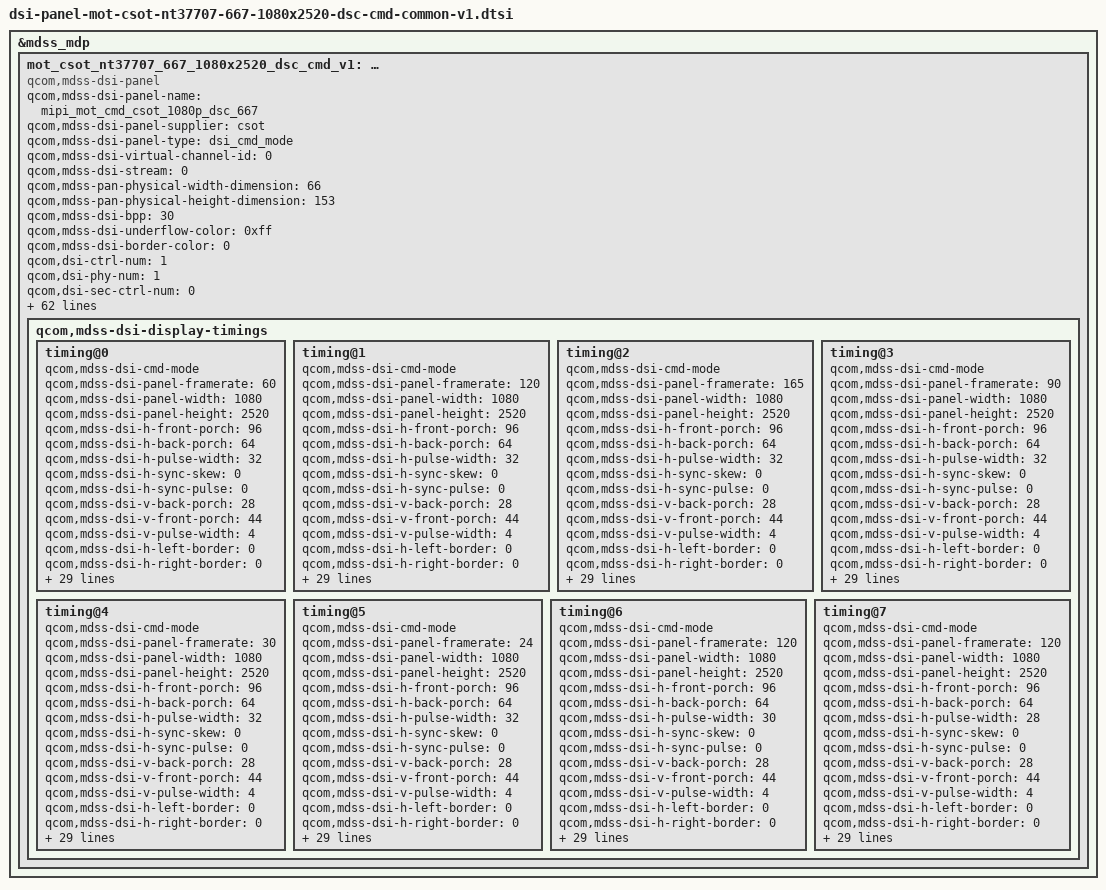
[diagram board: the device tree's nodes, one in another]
/* Copyright (c) 2019-2020, The Linux Foundation. All rights reserved.
 *
 * This program is free software; you can redistribute it and/or modify
 * it under the terms of the GNU General Public License version 2 and
 * only version 2 as published by the Free Software Foundation.
 *
 * This program is distributed in the hope that it will be useful,
 * but WITHOUT ANY WARRANTY; without even the implied warranty of
 * MERCHANTABILITY or FITNESS FOR A PARTICULAR PURPOSE.  See the
 * GNU General Public License for more details.
 */
&mdss_mdp {
mot_csot_nt37707_667_1080x2520_dsc_cmd_v1: qcom,mdss_dsi_mot_csot_nt37707_667_1080x2520_dsc_cmd_v1 {
compatible = "qcom,mdss-dsi-panel";
qcom,mdss-dsi-panel-name = "mipi_mot_cmd_csot_1080p_dsc_667";
qcom,mdss-dsi-panel-supplier = "csot";
qcom,mdss-dsi-panel-type = "dsi_cmd_mode";
qcom,mdss-dsi-virtual-channel-id = <0>;
qcom,mdss-dsi-stream = <0>;
qcom,mdss-pan-physical-width-dimension = <66>;
qcom,mdss-pan-physical-height-dimension = <153>;
qcom,mdss-dsi-bpp = <30>;
qcom,mdss-dsi-underflow-color = <0xff>;
qcom,mdss-dsi-border-color = <0>;

qcom,dsi-ctrl-num = <1>;
qcom,dsi-phy-num = <1>;
qcom,dsi-sec-ctrl-num = <0>;
qcom,dsi-sec-phy-num = <0>;

qcom,mdss-dsi-traffic-mode = "burst_mode";
qcom,mdss-dsi-bllp-eof-power-mode;
qcom,mdss-dsi-bllp-power-mode;
qcom,mdss-dsi-lane-0-state;
qcom,mdss-dsi-lane-1-state;
qcom,mdss-dsi-lane-2-state;
qcom,mdss-dsi-lane-3-state;

qcom,mdss-dsi-dma-trigger = "trigger_sw";
qcom,mdss-dsi-mdp-trigger = "none";
qcom,mdss-dsi-reset-sequence = <0 3>, <1 1>, <0 1>, <1 20>;
qcom,mdss-dsi-lp11-init;
qcom,mdss-dsi-tx-eot-append;
qcom,mdss-dsi-te-pin-select = <1>;
qcom,mdss-dsi-te-dcs-command = <1>;
qcom,mdss-dsi-te-using-te-pin;

//qcom,bklt-dcs-2bytes-enabled;
qcom,mdss-dsi-bl-min-level = <4>;
qcom,mdss-dsi-bl-max-level = <14056>;
qcom,mdss-dsi-bl-pmic-control-type = "bl_ctrl_dcs";

qcom,mdss-dsi-panel-hdr-enabled;
qcom,mdss-dsi-panel-hdr-color-primaries = <14500 15500 32000
	        17000 15500 30000 8000 3000>;
qcom,mdss-dsi-panel-peak-brightness = <4200000>;

qcom,mdss-dsi-panel-blackness-level = <3230>;

qcom,mdss-dsi-dc-off-command = [
		39 00 00 40 00 00 02 6F 01
		39 00 00 40 00 00 02 8B 00
		39 00 00 40 00 00 06 F0 55 AA 52 08 01
		39 00 00 40 00 00 02 6F 36
		39 00 00 40 00 00 07 C6 02 10 EE 1E 00 5E
		39 00 00 40 00 00 02 6F 6F
		39 00 00 00 00 00 07 E2 02 10 EE 1E 00 5E
		];

qcom,mdss-dsi-dc-off-command-state = "dsi_hs_mode";
qcom,mdss-dsi-dc-on-command = [
		39 00 00 40 00 00 02 6F 01
		39 00 00 40 00 00 02 8B 81
		39 00 00 40 00 00 06 F0 55 AA 52 08 01
		39 00 00 40 00 00 02 6F 36
		39 00 00 40 00 00 07 C6 02 10 EE 19 00 5E
		39 00 00 40 00 00 02 6F 6F
		39 00 00 00 00 00 07 E2 02 10 EE 19 00 5E
		];
qcom,mdss-dsi-dc-on-command-state = "dsi_hs_mode";
//qcom,mdss-dsi-nt37705-dc-detect-fps;
qcom,check_pcd;
qcom,pcd-reg-read-enabled;
qcom,pcd-reg-check-before-read;
qcom,mdss-dsi-panel-pcd-reg-read-length = <1>;
qcom,mdss-dsi-panel-pcd-reg-mask = <0xFF>;
qcom,mdss-dsi-panel-pcd-reg-command = [06 01 00 01 00 00 01 D0];
qcom,mdss-dsi-panel-pcd-reg-pass-array-size = <4>;
qcom,mdss-dsi-panel-pcd-reg-pass-array = <0x80 0x81 0x82 0x83>;
qcom,mdss-dsi-panel-pcd-reg-read-delay-ms = <60>;
qcom,mdss-dsi-panel-pcd-reg-seq-interval = <30>; //pcd reg read seq interval per screen on.
qcom,mdss-dsi-panel-pcd-check-time-interval-in-minutes = <480>; //480 minutes/8hours for pcd reg read time interval

qcom,apl-enabled;
qcom,mdss-dsi-panel-APL-THRESHOLD-BL = <15412>;
qcom,mdss-dsi-panel-APL-FUNC-ID = <0>;
qcom,mdss-dsi-panel-apl-on-command = [
		39 00 00 40 00 00 02 6F 07
		39 00 00 00 00 00 02 51 80
		];
qcom,mdss-dsi-panel-apl-off-command = [
		39 00 00 40 00 00 02 6F 07
		39 00 00 00 00 00 02 51 00
		];

qcom,mdss-dsi-hbm-off-command = [
		39 00 00 40 00 00 02 6F 07
		39 00 00 40 00 00 02 51 00
		39 00 00 00 00 00 03 51 2C 50
		];
qcom,mdss-dsi-hbm-off-command-state = "dsi_hs_mode";
qcom,mdss-dsi-hbm-on-command = [
		39 00 00 40 00 00 02 6F 07
		39 00 00 40 00 00 02 51 80
		39 00 00 00 00 00 03 51 3F FC
		];
qcom,mdss-dsi-hbm-on-command-state = "dsi_hs_mode";

qcom,mdss-dsi-display-timings {
	timing@0{
		qcom,mdss-dsi-cmd-mode;
		qcom,mdss-dsi-panel-framerate = <60>;
		qcom,mdss-dsi-panel-width = <1080>;
		qcom,mdss-dsi-panel-height = <2520>;
		qcom,mdss-dsi-h-front-porch = <96>;
		qcom,mdss-dsi-h-back-porch = <64>;
		qcom,mdss-dsi-h-pulse-width = <32>;
		qcom,mdss-dsi-h-sync-skew = <0>;
		qcom,mdss-dsi-h-sync-pulse = <0>;
		qcom,mdss-dsi-v-back-porch = <28>;
		qcom,mdss-dsi-v-front-porch = <44>;
		qcom,mdss-dsi-v-pulse-width = <4>;
		qcom,mdss-dsi-h-left-border = <0>;
		qcom,mdss-dsi-h-right-border = <0>;
		qcom,mdss-dsi-v-top-border = <0>;
		qcom,mdss-dsi-v-bottom-border = <0>;
		qcom,mdss-dsi-timing-switch-command = [
			39 00 00 40 00 00 02 6F 04
			39 00 00 40 00 00 02 35 00
			39 00 00 40 00 00 02 53 20
			39 00 00 40 00 00 02 5A 02
			39 00 00 40 00 00 02 2F 30
			39 00 00 40 00 00 03 6D 01 00
			39 00 00 40 00 00 02 6F 06
			39 00 00 40 00 00 02 6D 03
			39 00 00 40 00 00 02 6F 02
			39 00 00 40 00 00 02 8C 10
			39 00 00 00 11 00 02 8C 02
		];
		qcom,mdss-dsi-on-command = [
		39 00 00 40 00 00 06 F0 55 AA 52 08 01
		39 00 00 40 00 00 02 6F 2F
		39 00 00 40 00 00 02 C3 00
		39 00 00 40 00 00 02 6F 00
		39 00 00 40 00 00 06 C3 99 29 02 60 E3
		39 00 00 40 00 00 02 6F 06
		39 00 00 40 00 00 02 C3 29
		39 00 00 40 00 00 02 6F 08
		39 00 00 40 00 00 03 C3 60 E3
		39 00 00 40 00 00 02 6F 0B
		39 00 00 40 00 00 25 C3 3F 41 2A 3F 52 EB 3F 1D DF 3F 3B B0 3F 41 95 3F 0D 75 3F 4B 9A 3F 4C 43 3F 41 95 3F 0D 75 01 10 00 00 10 00
		39 00 00 40 00 00 02 6F 30
		39 00 00 40 00 00 06 C3 00 AA 02 AA 02
		39 00 00 40 00 00 02 6F 00
		39 00 00 40 00 00 02 C3 DD
		39 00 00 40 00 00 02 6F 04
		39 00 00 40 00 00 02 C3 07
		39 00 00 40 00 00 02 6F 09
		39 00 00 40 00 00 02 C3 07
		39 00 00 40 00 00 06 F0 55 AA 52 08 01
		39 00 00 40 00 00 04 C4 00 92 00
		39 00 00 40 00 00 02 6F 01
		39 00 00 40 00 00 02 8D 20
		39 00 00 40 00 00 02 6F 06
		39 00 00 40 00 00 02 8D 05
		39 00 00 40 00 00 06 F0 55 AA 52 08 00
		39 00 00 40 00 00 03 B2 09 60
		39 00 00 40 00 00 02 6F 05
		39 00 00 40 00 00 03 B2 05 05

		39 00 00 40 00 00 06 F0 55 AA 52 08 09
		39 00 00 40 00 00 03 D0 FF 00
		39 00 00 40 00 00 02 6F 02
		39 00 00 40 00 00 03 D0 06 64
		39 00 00 40 00 00 02 6F 04
		39 00 00 40 00 00 03 D0 09 04
		39 00 00 40 00 00 02 6F 06
		39 00 00 40 00 00 03 D0 0D BF
		39 00 00 40 00 00 02 6F 08
		39 00 00 40 00 00 03 D0 0D C0
		39 00 00 40 00 00 02 6F 0A
		39 00 00 40 00 00 03 D0 1D 24
		39 00 00 40 00 00 02 6F 0C
		39 00 00 40 00 00 03 D0 2C 50
		39 00 00 40 00 00 02 6F 0E
		39 00 00 40 00 00 07 D0 10 00 00 00 00 00
		39 00 00 40 00 00 02 6F 14
		39 00 00 40 00 00 07 D0 10 00 00 00 00 00
		39 00 00 40 00 00 02 6F 1A
		39 00 00 40 00 00 07 D0 00 00 00 00 00 00
		39 00 00 40 00 00 02 6F 20
		39 00 00 40 00 00 07 D0 00 00 00 00 00 00
		39 00 00 40 00 00 02 6F 26
		39 00 00 40 00 00 07 D0 1F 00 00 00 00 00
		39 00 00 40 00 00 02 6F 2C
		39 00 00 40 00 00 07 D0 1F 00 00 00 00 00
		39 00 00 40 00 00 02 6F 32
		39 00 00 40 00 00 07 D0 00 00 00 00 00 00
		39 00 00 40 00 00 02 6F 38
		39 00 00 40 00 00 07 D0 00 00 00 00 00 00
		39 00 00 40 00 00 02 62 80

		39 00 00 40 00 00 06 F0 55 AA 52 08 00
		39 00 00 40 00 00 02 6F 78
		39 00 00 40 00 00 18 B0 10 00 2A 00 C2 01 DA 03 7C 05 B1 08 80 0B EE 0F FF 05 55 05 56 05 55
		39 00 00 40 00 00 02 6F 6F
		39 00 00 40 00 00 07 B0 02 1C 04 38 02 1C
		39 00 00 40 00 00 06 F0 55 AA 52 08 08
		39 00 00 40 00 00 17 C1 8D FF DD FF FF DD FF FF DD FF FF DD FF FF DD FF FF AB FC 45 0D FF
		39 00 00 40 00 00 02 6F 23
		39 00 00 40 00 00 15 C1 0D FF DD FF FF DD FF FF DD FF FF DD FF FF DD FF FF AB FC 45
		39 00 00 40 00 00 02 6F 37
		39 00 00 40 00 00 15 C1 0D FF DD FF FF DD FF FF DD FF FF DD FF FF DD FF FF FF FF FF
		39 00 00 40 00 00 02 6F 4B
		39 00 00 40 00 00 15 C1 0D FF DD FF FF DD FF FF DD FF FF DD FF FF DD FF FF AB FC 45
		39 00 00 40 00 00 02 6F 5F
		39 00 00 40 00 00 15 C1 0D FF DD FF FF DD FF FF DD FF FF DD FF FF DD FF FF FF FF FF
		39 00 00 40 00 00 02 6F 73
		39 00 00 40 00 00 15 C1 0D FF DD FF FF DD FF FF DD FF FF DD FF FF DD FF FF AB FC 45
		39 00 00 40 00 00 11 BA 00 01 03 A4 03 A4 05 B8 05 B8 07 D8 07 D8 0A 84
		39 00 00 40 00 00 02 6F 10
		39 00 00 40 00 00 11 BA 0A 84 0D BF 0D BF 0D C0 0D C0 1D 24 1D 24 2C 50
		39 00 00 40 00 00 02 6F 20
		39 00 00 40 00 00 0D BA 2C 50 36 E8 36 E8 3C 34 3C 34 3F FC
		39 00 00 40 00 00 02 6F 20
		39 00 00 40 00 00 04 C1 04 52 CD
		39 00 00 40 00 00 02 6F 1D
		39 00 00 40 00 00 04 C1 00 80 FF
		39 00 00 40 00 00 02 6F 07
		39 00 00 40 00 00 02 51 00
		39 00 00 40 00 00 06 F0 55 AA 52 08 00
		39 00 00 40 00 00 02 C7 22
		39 00 00 40 00 00 02 6F 31
		39 00 00 40 00 00 03 C0 00 12
		39 00 00 40 00 00 02 6F 35
		39 00 00 40 00 00 03 C0 33 34
		39 00 00 40 00 00 06 F0 55 AA 52 08 04
		39 00 00 40 00 00 02 C0 20
		39 00 00 40 00 00 02 B1 01
		39 00 00 40 00 00 02 6F 0A
		39 00 00 40 00 00 02 B1 20
		39 00 00 40 00 00 02 6F 07
		39 00 00 40 00 00 04 B1 00 02 1C
		39 00 00 40 00 00 02 6F 0B
		39 00 00 40 00 00 02 B1 02
		39 00 00 40 00 00 02 C4 10
		39 00 00 40 00 00 05 FF AA 55 A5 80
		39 00 00 40 00 00 02 6F 0A
		39 00 00 40 00 00 06 F6 70 70 70 70 70
		39 00 00 40 00 00 02 6F 07
		39 00 00 40 00 00 02 F8 4D
		39 00 00 40 00 00 02 6F 23
		39 00 00 40 00 00 02 F8 4D
		39 00 00 40 00 00 05 FF AA 55 A5 81
		39 00 00 40 00 00 02 6F 0C
		39 00 00 40 00 00 02 FD 08
		39 00 00 40 00 00 02 6F 10
		39 00 00 40 00 00 02 FB 40
		39 00 00 40 00 00 02 6F 13
		39 00 00 40 00 00 02 F9 00
		39 00 00 40 00 00 02 17 30
		39 00 00 40 00 00 05 2A 00 00 04 37
		39 00 00 40 00 00 05 2B 00 00 09 D7
		39 00 00 40 00 00 02 90 03
		39 00 00 40 00 00 02 6F 01
		39 00 00 40 00 00 02 90 43
		39 00 00 40 00 00 13 91 AB A8 00 14 C2 00 02 0E 01 E8 00 07 05 0E 05 16 10 F0
		39 00 00 40 00 00 02 6F 06
		39 00 00 40 00 00 02 6D 04

		39 00 00 40 00 00 02 6F 04
		39 00 00 40 00 00 02 35 00
		39 00 00 40 00 00 02 53 20
		39 00 00 40 00 00 02 5A 02
		39 00 00 40 00 00 02 2F 30
		39 00 00 40 00 00 03 6D 01 00
		39 00 00 40 00 00 02 6F 06
		39 00 00 40 00 00 02 6D 03
		39 00 00 40 00 00 02 6F 02
		39 00 00 40 00 00 02 8C 10
		39 00 00 40 00 00 02 8C 02

		39 00 00 40 00 00 03 5F 00 00
		//39 00 00 40 00 00 02 35 00
		39 00 00 40 00 00 03 51 00 00
		39 00 00 40 00 00 02 6F 04
		39 00 00 40 00 00 03 51 3F FC
		//39 00 00 40 00 00 02 53 20
		39 00 00 40 00 00 06 F0 55 AA 52 08 01
		39 00 00 40 00 00 02 6F 02
		39 00 00 40 00 00 03 C7 00 00
		39 00 00 00 00 00 02 26 00
                05 00 00 00 78 00 01 11
                05 00 00 00 00 00 01 29];	/* display on */
		qcom,mdss-dsi-off-command = [
			05 00 00 00 00 00 01 28		/* display_off */
			05 00 00 00 64 00 01 10];	/* enter sleep mode */

		qcom,mdss-dsi-on-command-state = "dsi_lp_mode";
		qcom,mdss-dsi-off-command-state = "dsi_lp_mode";
		qcom,mdss-dsi-timing-switch-command-state =
			"dsi_hs_mode";
		qcom,compression-mode = "dsc";
		/* Why QCOM doesn't use this, even it used 2 encoder
		 * as for that dsi_sw43404_amoled_cmd, for ex */
		/* qcom,mdss-dsc-encoders = <2>; */
		qcom,mdss-dsc-version = <0x11>;
		qcom,mdss-dsc-slice-height = <20>;
		qcom,mdss-dsc-slice-width = <540>;
		qcom,mdss-dsc-slice-per-pkt = <2>;
		qcom,mdss-dsc-bit-per-component = <10>;
		qcom,mdss-dsc-bit-per-pixel = <8>;
		qcom,mdss-dsc-block-prediction-enable;
		qcom,mdss-dsc-novateck-ic;

		qcom,mdss-dsi-pcd-check-enable-command = [
			39 00 00 40 00 00 06 F0 55 AA 52 08 01
			39 00 00 40 00 00 02 6F 01
			39 00 00 00 00 00 06 D0 80 00 30 00 01
			];
		qcom,mdss-dsi-pcd-check-enable-command-state = "dsi_hs_mode";
		qcom,mdss-dsi-pcd-check-disable-command = [
			39 00 00 40 00 00 06 F0 55 AA 52 08 01
			39 00 00 40 00 00 02 6F 01
			39 00 00 00 00 00 06 D0 00 00 30 00 01
			];
		qcom,mdss-dsi-pcd-check-disable-command-state = "dsi_hs_mode";
	};

	timing@1{
		qcom,mdss-dsi-cmd-mode;
		qcom,mdss-dsi-panel-framerate = <120>;
		qcom,mdss-dsi-panel-width = <1080>;
		qcom,mdss-dsi-panel-height = <2520>;
		qcom,mdss-dsi-h-front-porch = <96>;
		qcom,mdss-dsi-h-back-porch = <64>;
		qcom,mdss-dsi-h-pulse-width = <32>;
		qcom,mdss-dsi-h-sync-skew = <0>;
		qcom,mdss-dsi-h-sync-pulse = <0>;
		qcom,mdss-dsi-v-back-porch = <28>;
		qcom,mdss-dsi-v-front-porch = <44>;
		qcom,mdss-dsi-v-pulse-width = <4>;
		qcom,mdss-dsi-h-left-border = <0>;
		qcom,mdss-dsi-h-right-border = <0>;
		qcom,mdss-dsi-v-top-border = <0>;
		qcom,mdss-dsi-v-bottom-border = <0>;
		qcom,mdss-dsi-timing-switch-command = [
			39 00 00 40 00 00 02 6F 04
			39 00 00 40 00 00 02 35 00
			39 00 00 40 00 00 02 53 20
			39 00 00 00 09 00 02 2F 00
		];
		qcom,mdss-dsi-on-command = [
		39 00 00 40 00 00 06 F0 55 AA 52 08 01
		39 00 00 40 00 00 02 6F 2F
		39 00 00 40 00 00 02 C3 00
		39 00 00 40 00 00 02 6F 00
		39 00 00 40 00 00 06 C3 99 29 02 60 E3
		39 00 00 40 00 00 02 6F 06
		39 00 00 40 00 00 02 C3 29
		39 00 00 40 00 00 02 6F 08
		39 00 00 40 00 00 03 C3 60 E3
		39 00 00 40 00 00 02 6F 0B
		39 00 00 40 00 00 25 C3 3F 41 2A 3F 52 EB 3F 1D DF 3F 3B B0 3F 41 95 3F 0D 75 3F 4B 9A 3F 4C 43 3F 41 95 3F 0D 75 01 10 00 00 10 00
		39 00 00 40 00 00 02 6F 30
		39 00 00 40 00 00 06 C3 00 AA 02 AA 02
		39 00 00 40 00 00 02 6F 00
		39 00 00 40 00 00 02 C3 DD
		39 00 00 40 00 00 02 6F 04
		39 00 00 40 00 00 02 C3 07
		39 00 00 40 00 00 02 6F 09
		39 00 00 40 00 00 02 C3 07
		39 00 00 40 00 00 06 F0 55 AA 52 08 01
		39 00 00 40 00 00 04 C4 00 92 00
		39 00 00 40 00 00 02 6F 06
		39 00 00 40 00 00 02 8D 05
		39 00 00 40 00 00 06 F0 55 AA 52 08 00
		39 00 00 40 00 00 03 B2 09 60
		39 00 00 40 00 00 02 6F 05
		39 00 00 40 00 00 03 B2 05 05

		39 00 00 40 00 00 06 F0 55 AA 52 08 09
		39 00 00 40 00 00 03 D0 FF 00
		39 00 00 40 00 00 02 6F 02
		39 00 00 40 00 00 03 D0 06 64
		39 00 00 40 00 00 02 6F 04
		39 00 00 40 00 00 03 D0 09 04
		39 00 00 40 00 00 02 6F 06
		39 00 00 40 00 00 03 D0 0D BF
		39 00 00 40 00 00 02 6F 08
		39 00 00 40 00 00 03 D0 0D C0
		39 00 00 40 00 00 02 6F 0A
		39 00 00 40 00 00 03 D0 1D 24
		39 00 00 40 00 00 02 6F 0C
		39 00 00 40 00 00 03 D0 2C 50
		39 00 00 40 00 00 02 6F 0E
		39 00 00 40 00 00 07 D0 10 00 00 00 00 00
		39 00 00 40 00 00 02 6F 14
		39 00 00 40 00 00 07 D0 10 00 00 00 00 00
		39 00 00 40 00 00 02 6F 1A
		39 00 00 40 00 00 07 D0 00 00 00 00 00 00
		39 00 00 40 00 00 02 6F 20
		39 00 00 40 00 00 07 D0 00 00 00 00 00 00
		39 00 00 40 00 00 02 6F 26
		39 00 00 40 00 00 07 D0 1F 00 00 00 00 00
		39 00 00 40 00 00 02 6F 2C
		39 00 00 40 00 00 07 D0 1F 00 00 00 00 00
		39 00 00 40 00 00 02 6F 32
		39 00 00 40 00 00 07 D0 00 00 00 00 00 00
		39 00 00 40 00 00 02 6F 38
		39 00 00 40 00 00 07 D0 00 00 00 00 00 00
		39 00 00 40 00 00 02 62 80

		39 00 00 40 00 00 06 F0 55 AA 52 08 00
		39 00 00 40 00 00 02 6F 78
		39 00 00 40 00 00 18 B0 10 00 2A 00 C2 01 DA 03 7C 05 B1 08 80 0B EE 0F FF 05 55 05 56 05 55
		39 00 00 40 00 00 02 6F 6F
		39 00 00 40 00 00 07 B0 02 1C 04 38 02 1C
		39 00 00 40 00 00 06 F0 55 AA 52 08 08
		39 00 00 40 00 00 17 C1 8D FF DD FF FF DD FF FF DD FF FF DD FF FF DD FF FF AB FC 45 0D FF
		39 00 00 40 00 00 02 6F 23
		39 00 00 40 00 00 15 C1 0D FF DD FF FF DD FF FF DD FF FF DD FF FF DD FF FF AB FC 45
		39 00 00 40 00 00 02 6F 37
		39 00 00 40 00 00 15 C1 0D FF DD FF FF DD FF FF DD FF FF DD FF FF DD FF FF FF FF FF
		39 00 00 40 00 00 02 6F 4B
		39 00 00 40 00 00 15 C1 0D FF DD FF FF DD FF FF DD FF FF DD FF FF DD FF FF AB FC 45
		39 00 00 40 00 00 02 6F 5F
		39 00 00 40 00 00 15 C1 0D FF DD FF FF DD FF FF DD FF FF DD FF FF DD FF FF FF FF FF
		39 00 00 40 00 00 02 6F 73
		39 00 00 40 00 00 15 C1 0D FF DD FF FF DD FF FF DD FF FF DD FF FF DD FF FF AB FC 45
		39 00 00 40 00 00 11 BA 00 01 03 A4 03 A4 05 B8 05 B8 07 D8 07 D8 0A 84
		39 00 00 40 00 00 02 6F 10
		39 00 00 40 00 00 11 BA 0A 84 0D BF 0D BF 0D C0 0D C0 1D 24 1D 24 2C 50
		39 00 00 40 00 00 02 6F 20
		39 00 00 40 00 00 0D BA 2C 50 36 E8 36 E8 3C 34 3C 34 3F FC
		39 00 00 40 00 00 02 6F 20
		39 00 00 40 00 00 04 C1 04 52 CD
		39 00 00 40 00 00 02 6F 1D
		39 00 00 40 00 00 04 C1 00 80 FF
		39 00 00 40 00 00 02 6F 07
		39 00 00 40 00 00 02 51 00
		39 00 00 40 00 00 06 F0 55 AA 52 08 00
		39 00 00 40 00 00 02 C7 22
		39 00 00 40 00 00 02 6F 31
		39 00 00 40 00 00 03 C0 00 12
		39 00 00 40 00 00 02 6F 35
		39 00 00 40 00 00 03 C0 33 34
		39 00 00 40 00 00 06 F0 55 AA 52 08 04
		39 00 00 40 00 00 02 C0 20
		39 00 00 40 00 00 02 B1 01
		39 00 00 40 00 00 02 6F 0A
		39 00 00 40 00 00 02 B1 20
		39 00 00 40 00 00 02 6F 07
		39 00 00 40 00 00 04 B1 00 02 1C
		39 00 00 40 00 00 02 6F 0B
		39 00 00 40 00 00 02 B1 02
		39 00 00 40 00 00 02 C4 10
		39 00 00 40 00 00 05 FF AA 55 A5 80
		39 00 00 40 00 00 02 6F 0A
		39 00 00 40 00 00 06 F6 70 70 70 70 70
		39 00 00 40 00 00 02 6F 07
		39 00 00 40 00 00 02 F8 4D
		39 00 00 40 00 00 02 6F 23
		39 00 00 40 00 00 02 F8 4D
		39 00 00 40 00 00 05 FF AA 55 A5 81
		39 00 00 40 00 00 02 6F 0C
		39 00 00 40 00 00 02 FD 08
		39 00 00 40 00 00 02 6F 10
		39 00 00 40 00 00 02 FB 40
		39 00 00 40 00 00 02 6F 13
		39 00 00 40 00 00 02 F9 00
		39 00 00 40 00 00 02 17 30
		39 00 00 40 00 00 05 2A 00 00 04 37
		39 00 00 40 00 00 05 2B 00 00 09 D7
		39 00 00 40 00 00 02 90 03
		39 00 00 40 00 00 02 6F 01
		39 00 00 40 00 00 02 90 43
		39 00 00 40 00 00 13 91 AB A8 00 14 C2 00 02 0E 01 E8 00 07 05 0E 05 16 10 F0
		39 00 00 40 00 00 02 6F 06
		39 00 00 40 00 00 02 6D 04

		39 00 00 40 00 00 02 6F 04
		39 00 00 40 00 00 02 35 00
		39 00 00 40 00 00 02 53 20
		39 00 00 40 00 00 02 2F 00

		39 00 00 40 00 00 03 5F 00 00
		//39 00 00 40 00 00 02 35 00
		39 00 00 40 00 00 03 51 00 00
		39 00 00 40 00 00 02 6F 04
		39 00 00 40 00 00 03 51 3F FC
		//39 00 00 40 00 00 02 53 20
		39 00 00 40 00 00 06 F0 55 AA 52 08 01
		39 00 00 40 00 00 02 6F 02
		39 00 00 40 00 00 03 C7 00 00
		39 00 00 00 00 00 02 26 00
                05 00 00 00 78 00 01 11
                05 00 00 00 00 00 01 29];	/* display on */
		qcom,mdss-dsi-off-command = [
			05 00 00 00 00 00 01 28		/* display_off */
			05 00 00 00 78 00 01 10];	/* enter sleep mode */

		qcom,mdss-dsi-on-command-state = "dsi_lp_mode";
		qcom,mdss-dsi-off-command-state = "dsi_lp_mode";
		qcom,mdss-dsi-timing-switch-command-state =
			"dsi_hs_mode";
		qcom,compression-mode = "dsc";
		/* Why QCOM doesn't use this, even it used 2 encoder
		 * as for that dsi_sw43404_amoled_cmd, for ex */
		/* qcom,mdss-dsc-encoders = <2>; */
		qcom,mdss-dsc-version = <0x11>;
		qcom,mdss-dsc-slice-height = <20>;
		qcom,mdss-dsc-slice-width = <540>;
		qcom,mdss-dsc-slice-per-pkt = <2>;
		qcom,mdss-dsc-bit-per-component = <10>;
		qcom,mdss-dsc-bit-per-pixel = <8>;
		qcom,mdss-dsc-block-prediction-enable;
		qcom,mdss-dsc-novateck-ic;

		qcom,mdss-dsi-pcd-check-enable-command = [
			39 00 00 40 00 00 06 F0 55 AA 52 08 01
			39 00 00 40 00 00 02 6F 01
			39 00 00 00 00 00 06 D0 80 00 30 00 01
			];
		qcom,mdss-dsi-pcd-check-enable-command-state = "dsi_hs_mode";
		qcom,mdss-dsi-pcd-check-disable-command = [
			39 00 00 40 00 00 06 F0 55 AA 52 08 01
			39 00 00 40 00 00 02 6F 01
			39 00 00 00 00 00 06 D0 00 00 30 00 01
			];
		qcom,mdss-dsi-pcd-check-disable-command-state = "dsi_hs_mode";
	};

	timing@2{
		qcom,mdss-dsi-cmd-mode;
		qcom,mdss-dsi-panel-framerate = <165>;
		qcom,mdss-dsi-panel-width = <1080>;
		qcom,mdss-dsi-panel-height = <2520>;
		qcom,mdss-dsi-h-front-porch = <96>;
		qcom,mdss-dsi-h-back-porch = <64>;
		qcom,mdss-dsi-h-pulse-width = <32>;
		qcom,mdss-dsi-h-sync-skew = <0>;
		qcom,mdss-dsi-h-sync-pulse = <0>;
		qcom,mdss-dsi-v-back-porch = <28>;
		qcom,mdss-dsi-v-front-porch = <44>;
		qcom,mdss-dsi-v-pulse-width = <4>;
		qcom,mdss-dsi-h-left-border = <0>;
		qcom,mdss-dsi-h-right-border = <0>;
		qcom,mdss-dsi-v-top-border = <0>;
		qcom,mdss-dsi-v-bottom-border = <0>;
		qcom,mdss-dsi-timing-switch-command = [
			39 00 00 40 00 00 02 6F 04
			39 00 00 40 00 00 02 35 00
			39 00 00 40 00 00 02 53 20
			39 00 00 00 00 00 02 2F 03
		];
		qcom,mdss-dsi-on-command = [
		39 00 00 40 00 00 06 F0 55 AA 52 08 01
		39 00 00 40 00 00 02 6F 2F
		39 00 00 40 00 00 02 C3 00
		39 00 00 40 00 00 02 6F 00
		39 00 00 40 00 00 06 C3 99 29 02 60 E3
		39 00 00 40 00 00 02 6F 06
		39 00 00 40 00 00 02 C3 29
		39 00 00 40 00 00 02 6F 08
		39 00 00 40 00 00 03 C3 60 E3
		39 00 00 40 00 00 02 6F 0B
		39 00 00 40 00 00 25 C3 3F 41 2A 3F 52 EB 3F 1D DF 3F 3B B0 3F 41 95 3F 0D 75 3F 4B 9A 3F 4C 43 3F 41 95 3F 0D 75 01 10 00 00 10 00
		39 00 00 40 00 00 02 6F 30
		39 00 00 40 00 00 06 C3 00 AA 02 AA 02
		39 00 00 40 00 00 02 6F 00
		39 00 00 40 00 00 02 C3 DD
		39 00 00 40 00 00 02 6F 04
		39 00 00 40 00 00 02 C3 07
		39 00 00 40 00 00 02 6F 09
		39 00 00 40 00 00 02 C3 07
		39 00 00 40 00 00 06 F0 55 AA 52 08 01
		39 00 00 40 00 00 04 C4 00 92 00
		39 00 00 40 00 00 02 6F 06
		39 00 00 40 00 00 02 8D 05
		39 00 00 40 00 00 06 F0 55 AA 52 08 00
		39 00 00 40 00 00 03 B2 09 60
		39 00 00 40 00 00 02 6F 05
		39 00 00 40 00 00 03 B2 05 05

		39 00 00 40 00 00 06 F0 55 AA 52 08 09
		39 00 00 40 00 00 03 D0 FF 00
		39 00 00 40 00 00 02 6F 02
		39 00 00 40 00 00 03 D0 06 64
		39 00 00 40 00 00 02 6F 04
		39 00 00 40 00 00 03 D0 09 04
		39 00 00 40 00 00 02 6F 06
		39 00 00 40 00 00 03 D0 0D BF
		39 00 00 40 00 00 02 6F 08
		39 00 00 40 00 00 03 D0 0D C0
		39 00 00 40 00 00 02 6F 0A
		39 00 00 40 00 00 03 D0 1D 24
		39 00 00 40 00 00 02 6F 0C
		39 00 00 40 00 00 03 D0 2C 50
		39 00 00 40 00 00 02 6F 0E
		39 00 00 40 00 00 07 D0 10 00 00 00 00 00
		39 00 00 40 00 00 02 6F 14
		39 00 00 40 00 00 07 D0 10 00 00 00 00 00
		39 00 00 40 00 00 02 6F 1A
		39 00 00 40 00 00 07 D0 00 00 00 00 00 00
		39 00 00 40 00 00 02 6F 20
		39 00 00 40 00 00 07 D0 00 00 00 00 00 00
		39 00 00 40 00 00 02 6F 26
		39 00 00 40 00 00 07 D0 1F 00 00 00 00 00
		39 00 00 40 00 00 02 6F 2C
		39 00 00 40 00 00 07 D0 1F 00 00 00 00 00
		39 00 00 40 00 00 02 6F 32
		39 00 00 40 00 00 07 D0 00 00 00 00 00 00
		39 00 00 40 00 00 02 6F 38
		39 00 00 40 00 00 07 D0 00 00 00 00 00 00
		39 00 00 40 00 00 02 62 80

		39 00 00 40 00 00 06 F0 55 AA 52 08 00
		39 00 00 40 00 00 02 6F 78
		39 00 00 40 00 00 18 B0 10 00 2A 00 C2 01 DA 03 7C 05 B1 08 80 0B EE 0F FF 05 55 05 56 05 55
		39 00 00 40 00 00 02 6F 6F
		39 00 00 40 00 00 07 B0 02 1C 04 38 02 1C
		39 00 00 40 00 00 06 F0 55 AA 52 08 08
		39 00 00 40 00 00 17 C1 8D FF DD FF FF DD FF FF DD FF FF DD FF FF DD FF FF AB FC 45 0D FF
		39 00 00 40 00 00 02 6F 23
		39 00 00 40 00 00 15 C1 0D FF DD FF FF DD FF FF DD FF FF DD FF FF DD FF FF AB FC 45
		39 00 00 40 00 00 02 6F 37
		39 00 00 40 00 00 15 C1 0D FF DD FF FF DD FF FF DD FF FF DD FF FF DD FF FF FF FF FF
		39 00 00 40 00 00 02 6F 4B
		39 00 00 40 00 00 15 C1 0D FF DD FF FF DD FF FF DD FF FF DD FF FF DD FF FF AB FC 45
		39 00 00 40 00 00 02 6F 5F
		39 00 00 40 00 00 15 C1 0D FF DD FF FF DD FF FF DD FF FF DD FF FF DD FF FF FF FF FF
		39 00 00 40 00 00 02 6F 73
		39 00 00 40 00 00 15 C1 0D FF DD FF FF DD FF FF DD FF FF DD FF FF DD FF FF AB FC 45
		39 00 00 40 00 00 11 BA 00 01 03 A4 03 A4 05 B8 05 B8 07 D8 07 D8 0A 84
		39 00 00 40 00 00 02 6F 10
		39 00 00 40 00 00 11 BA 0A 84 0D BF 0D BF 0D C0 0D C0 1D 24 1D 24 2C 50
		39 00 00 40 00 00 02 6F 20
		39 00 00 40 00 00 0D BA 2C 50 36 E8 36 E8 3C 34 3C 34 3F FC
		39 00 00 40 00 00 02 6F 20
		39 00 00 40 00 00 04 C1 04 52 CD
		39 00 00 40 00 00 02 6F 1D
		39 00 00 40 00 00 04 C1 00 80 FF
		39 00 00 40 00 00 02 6F 07
		39 00 00 40 00 00 02 51 00
		39 00 00 40 00 00 06 F0 55 AA 52 08 00
		39 00 00 40 00 00 02 C7 22
		39 00 00 40 00 00 02 6F 31
		39 00 00 40 00 00 03 C0 00 12
		39 00 00 40 00 00 02 6F 35
		39 00 00 40 00 00 03 C0 33 34
		39 00 00 40 00 00 06 F0 55 AA 52 08 04
		39 00 00 40 00 00 02 C0 20
		39 00 00 40 00 00 02 B1 01
		39 00 00 40 00 00 02 6F 0A
		39 00 00 40 00 00 02 B1 20
		39 00 00 40 00 00 02 6F 07
		39 00 00 40 00 00 04 B1 00 02 1C
		39 00 00 40 00 00 02 6F 0B
		39 00 00 40 00 00 02 B1 02
		39 00 00 40 00 00 02 C4 10
		39 00 00 40 00 00 05 FF AA 55 A5 80
		39 00 00 40 00 00 02 6F 0A
		39 00 00 40 00 00 06 F6 70 70 70 70 70
		39 00 00 40 00 00 02 6F 07
		39 00 00 40 00 00 02 F8 4D
		39 00 00 40 00 00 02 6F 23
		39 00 00 40 00 00 02 F8 4D
		39 00 00 40 00 00 05 FF AA 55 A5 81
		39 00 00 40 00 00 02 6F 0C
		39 00 00 40 00 00 02 FD 08
		39 00 00 40 00 00 02 6F 10
		39 00 00 40 00 00 02 FB 40
		39 00 00 40 00 00 02 6F 13
		39 00 00 40 00 00 02 F9 00
		39 00 00 40 00 00 02 17 30
		39 00 00 40 00 00 05 2A 00 00 04 37
		39 00 00 40 00 00 05 2B 00 00 09 D7
		39 00 00 40 00 00 02 90 03
		39 00 00 40 00 00 02 6F 01
		39 00 00 40 00 00 02 90 43
		39 00 00 40 00 00 13 91 AB A8 00 14 C2 00 02 0E 01 E8 00 07 05 0E 05 16 10 F0
		39 00 00 40 00 00 02 6F 06
		39 00 00 40 00 00 02 6D 04

		39 00 00 40 00 00 02 6F 04
		39 00 00 40 00 00 02 35 00
		39 00 00 40 00 00 02 53 20
		39 00 00 40 00 00 02 2F 03

		39 00 00 40 00 00 03 5F 00 00
		//39 00 00 40 00 00 02 35 00
		39 00 00 40 00 00 03 51 00 00
		39 00 00 40 00 00 02 6F 04
		39 00 00 40 00 00 03 51 3F FC
		//39 00 00 40 00 00 02 53 20
		39 00 00 40 00 00 06 F0 55 AA 52 08 01
		39 00 00 40 00 00 02 6F 02
		39 00 00 40 00 00 03 C7 00 00
		39 00 00 00 00 00 02 26 00
                05 00 00 00 78 00 01 11
                05 00 00 00 00 00 01 29];	/* display on */
		qcom,mdss-dsi-off-command = [
			05 00 00 00 00 00 01 28		/* display_off */
			05 00 00 00 64 00 01 10];	/* enter sleep mode */

		qcom,mdss-dsi-on-command-state = "dsi_lp_mode";
		qcom,mdss-dsi-off-command-state = "dsi_lp_mode";
		qcom,mdss-dsi-timing-switch-command-state =
			"dsi_hs_mode";
		qcom,compression-mode = "dsc";
		/* Why QCOM doesn't use this, even it used 2 encoder
		 * as for that dsi_sw43404_amoled_cmd, for ex */
		/* qcom,mdss-dsc-encoders = <2>; */
		qcom,mdss-dsc-version = <0x11>;
		qcom,mdss-dsc-slice-height = <20>;
		qcom,mdss-dsc-slice-width = <540>;
		qcom,mdss-dsc-slice-per-pkt = <2>;
		qcom,mdss-dsc-bit-per-component = <10>;
		qcom,mdss-dsc-bit-per-pixel = <8>;
		qcom,mdss-dsc-block-prediction-enable;
		qcom,mdss-dsc-novateck-ic;

		qcom,mdss-dsi-pcd-check-enable-command = [
			39 00 00 40 00 00 06 F0 55 AA 52 08 01
			39 00 00 40 00 00 02 6F 01
			39 00 00 00 00 00 06 D0 80 00 30 00 01
			];
		qcom,mdss-dsi-pcd-check-enable-command-state = "dsi_hs_mode";
		qcom,mdss-dsi-pcd-check-disable-command = [
			39 00 00 40 00 00 06 F0 55 AA 52 08 01
			39 00 00 40 00 00 02 6F 01
			39 00 00 00 00 00 06 D0 00 00 30 00 01
			];
		qcom,mdss-dsi-pcd-check-disable-command-state = "dsi_hs_mode";
	};

	timing@3{
		qcom,mdss-dsi-cmd-mode;
		qcom,mdss-dsi-panel-framerate = <90>;
		qcom,mdss-dsi-panel-width = <1080>;
		qcom,mdss-dsi-panel-height = <2520>;
		qcom,mdss-dsi-h-front-porch = <96>;
		qcom,mdss-dsi-h-back-porch = <64>;
		qcom,mdss-dsi-h-pulse-width = <32>;
		qcom,mdss-dsi-h-sync-skew = <0>;
		qcom,mdss-dsi-h-sync-pulse = <0>;
		qcom,mdss-dsi-v-back-porch = <28>;
		qcom,mdss-dsi-v-front-porch = <44>;
		qcom,mdss-dsi-v-pulse-width = <4>;
		qcom,mdss-dsi-h-left-border = <0>;
		qcom,mdss-dsi-h-right-border = <0>;
		qcom,mdss-dsi-v-top-border = <0>;
		qcom,mdss-dsi-v-bottom-border = <0>;
		qcom,mdss-dsi-timing-switch-command = [
			39 00 00 40 00 00 02 6F 04
			39 00 00 40 00 00 02 35 00
			39 00 00 40 00 00 02 53 20
			39 00 00 00 0C 00 02 2F 01
		];
		qcom,mdss-dsi-on-command = [
		39 00 00 40 00 00 06 F0 55 AA 52 08 01
		39 00 00 40 00 00 02 6F 2F
		39 00 00 40 00 00 02 C3 00
		39 00 00 40 00 00 02 6F 00
		39 00 00 40 00 00 06 C3 99 29 02 60 E3
		39 00 00 40 00 00 02 6F 06
		39 00 00 40 00 00 02 C3 29
		39 00 00 40 00 00 02 6F 08
		39 00 00 40 00 00 03 C3 60 E3
		39 00 00 40 00 00 02 6F 0B
		39 00 00 40 00 00 25 C3 3F 41 2A 3F 52 EB 3F 1D DF 3F 3B B0 3F 41 95 3F 0D 75 3F 4B 9A 3F 4C 43 3F 41 95 3F 0D 75 01 10 00 00 10 00
		39 00 00 40 00 00 02 6F 30
		39 00 00 40 00 00 06 C3 00 AA 02 AA 02
		39 00 00 40 00 00 02 6F 00
		39 00 00 40 00 00 02 C3 DD
		39 00 00 40 00 00 02 6F 04
		39 00 00 40 00 00 02 C3 07
		39 00 00 40 00 00 02 6F 09
		39 00 00 40 00 00 02 C3 07
		39 00 00 40 00 00 06 F0 55 AA 52 08 01
		39 00 00 40 00 00 04 C4 00 92 00
		39 00 00 40 00 00 02 6F 06
		39 00 00 40 00 00 02 8D 05
		39 00 00 40 00 00 06 F0 55 AA 52 08 00
		39 00 00 40 00 00 03 B2 09 60
		39 00 00 40 00 00 02 6F 05
		39 00 00 40 00 00 03 B2 05 05

		39 00 00 40 00 00 06 F0 55 AA 52 08 09
		39 00 00 40 00 00 03 D0 FF 00
		39 00 00 40 00 00 02 6F 02
		39 00 00 40 00 00 03 D0 06 64
		39 00 00 40 00 00 02 6F 04
		39 00 00 40 00 00 03 D0 09 04
		39 00 00 40 00 00 02 6F 06
		39 00 00 40 00 00 03 D0 0D BF
		39 00 00 40 00 00 02 6F 08
		39 00 00 40 00 00 03 D0 0D C0
		39 00 00 40 00 00 02 6F 0A
		39 00 00 40 00 00 03 D0 1D 24
		39 00 00 40 00 00 02 6F 0C
		39 00 00 40 00 00 03 D0 2C 50
		39 00 00 40 00 00 02 6F 0E
		39 00 00 40 00 00 07 D0 10 00 00 00 00 00
		39 00 00 40 00 00 02 6F 14
		39 00 00 40 00 00 07 D0 10 00 00 00 00 00
		39 00 00 40 00 00 02 6F 1A
		39 00 00 40 00 00 07 D0 00 00 00 00 00 00
		39 00 00 40 00 00 02 6F 20
		39 00 00 40 00 00 07 D0 00 00 00 00 00 00
		39 00 00 40 00 00 02 6F 26
		39 00 00 40 00 00 07 D0 1F 00 00 00 00 00
		39 00 00 40 00 00 02 6F 2C
		39 00 00 40 00 00 07 D0 1F 00 00 00 00 00
		39 00 00 40 00 00 02 6F 32
		39 00 00 40 00 00 07 D0 00 00 00 00 00 00
		39 00 00 40 00 00 02 6F 38
		39 00 00 40 00 00 07 D0 00 00 00 00 00 00
		39 00 00 40 00 00 02 62 80

		39 00 00 40 00 00 06 F0 55 AA 52 08 00
		39 00 00 40 00 00 02 6F 78
		39 00 00 40 00 00 18 B0 10 00 2A 00 C2 01 DA 03 7C 05 B1 08 80 0B EE 0F FF 05 55 05 56 05 55
		39 00 00 40 00 00 02 6F 6F
		39 00 00 40 00 00 07 B0 02 1C 04 38 02 1C
		39 00 00 40 00 00 06 F0 55 AA 52 08 08
		39 00 00 40 00 00 17 C1 8D FF DD FF FF DD FF FF DD FF FF DD FF FF DD FF FF AB FC 45 0D FF
		39 00 00 40 00 00 02 6F 23
		39 00 00 40 00 00 15 C1 0D FF DD FF FF DD FF FF DD FF FF DD FF FF DD FF FF AB FC 45
		39 00 00 40 00 00 02 6F 37
		39 00 00 40 00 00 15 C1 0D FF DD FF FF DD FF FF DD FF FF DD FF FF DD FF FF FF FF FF
		39 00 00 40 00 00 02 6F 4B
		39 00 00 40 00 00 15 C1 0D FF DD FF FF DD FF FF DD FF FF DD FF FF DD FF FF AB FC 45
		39 00 00 40 00 00 02 6F 5F
		39 00 00 40 00 00 15 C1 0D FF DD FF FF DD FF FF DD FF FF DD FF FF DD FF FF FF FF FF
		39 00 00 40 00 00 02 6F 73
		39 00 00 40 00 00 15 C1 0D FF DD FF FF DD FF FF DD FF FF DD FF FF DD FF FF AB FC 45
		39 00 00 40 00 00 11 BA 00 01 03 A4 03 A4 05 B8 05 B8 07 D8 07 D8 0A 84
		39 00 00 40 00 00 02 6F 10
		39 00 00 40 00 00 11 BA 0A 84 0D BF 0D BF 0D C0 0D C0 1D 24 1D 24 2C 50
		39 00 00 40 00 00 02 6F 20
		39 00 00 40 00 00 0D BA 2C 50 36 E8 36 E8 3C 34 3C 34 3F FC
		39 00 00 40 00 00 02 6F 20
		39 00 00 40 00 00 04 C1 04 52 CD
		39 00 00 40 00 00 02 6F 1D
		39 00 00 40 00 00 04 C1 00 80 FF
		39 00 00 40 00 00 02 6F 07
		39 00 00 40 00 00 02 51 00
		39 00 00 40 00 00 06 F0 55 AA 52 08 00
		39 00 00 40 00 00 02 C7 22
		39 00 00 40 00 00 02 6F 31
		39 00 00 40 00 00 03 C0 00 12
		39 00 00 40 00 00 02 6F 35
		39 00 00 40 00 00 03 C0 33 34
		39 00 00 40 00 00 06 F0 55 AA 52 08 04
		39 00 00 40 00 00 02 C0 20
		39 00 00 40 00 00 02 B1 01
		39 00 00 40 00 00 02 6F 0A
		39 00 00 40 00 00 02 B1 20
		39 00 00 40 00 00 02 6F 07
		39 00 00 40 00 00 04 B1 00 02 1C
		39 00 00 40 00 00 02 6F 0B
		39 00 00 40 00 00 02 B1 02
		39 00 00 40 00 00 02 C4 10
		39 00 00 40 00 00 05 FF AA 55 A5 80
		39 00 00 40 00 00 02 6F 0A
		39 00 00 40 00 00 06 F6 70 70 70 70 70
		39 00 00 40 00 00 02 6F 07
		39 00 00 40 00 00 02 F8 4D
		39 00 00 40 00 00 02 6F 23
		39 00 00 40 00 00 02 F8 4D
		39 00 00 40 00 00 05 FF AA 55 A5 81
		39 00 00 40 00 00 02 6F 0C
		39 00 00 40 00 00 02 FD 08
		39 00 00 40 00 00 02 6F 10
		39 00 00 40 00 00 02 FB 40
		39 00 00 40 00 00 02 6F 13
		39 00 00 40 00 00 02 F9 00
		39 00 00 40 00 00 02 17 30
		39 00 00 40 00 00 05 2A 00 00 04 37
		39 00 00 40 00 00 05 2B 00 00 09 D7
		39 00 00 40 00 00 02 90 03
		39 00 00 40 00 00 02 6F 01
		39 00 00 40 00 00 02 90 43
		39 00 00 40 00 00 13 91 AB A8 00 14 C2 00 02 0E 01 E8 00 07 05 0E 05 16 10 F0
		39 00 00 40 00 00 02 6F 06
		39 00 00 40 00 00 02 6D 04

		39 00 00 40 00 00 02 6F 04
		39 00 00 40 00 00 02 35 00
		39 00 00 40 00 00 02 53 20
		39 00 00 40 00 00 02 2F 01

		39 00 00 40 00 00 03 5F 00 00
		//39 00 00 40 00 00 02 35 00
		39 00 00 40 00 00 03 51 00 00
		39 00 00 40 00 00 02 6F 04
		39 00 00 40 00 00 03 51 3F FC
		//39 00 00 40 00 00 02 53 20
		39 00 00 40 00 00 06 F0 55 AA 52 08 01
		39 00 00 40 00 00 02 6F 02
		39 00 00 40 00 00 03 C7 00 00
		39 00 00 00 00 00 02 26 00
                05 00 00 00 78 00 01 11
                05 00 00 00 00 00 01 29];	/* display on */
		qcom,mdss-dsi-off-command = [
			05 00 00 00 00 00 01 28		/* display_off */
			05 00 00 00 64 00 01 10];	/* enter sleep mode */

		qcom,mdss-dsi-on-command-state = "dsi_lp_mode";
		qcom,mdss-dsi-off-command-state = "dsi_lp_mode";
		qcom,mdss-dsi-timing-switch-command-state =
			"dsi_hs_mode";
		qcom,compression-mode = "dsc";
		/* Why QCOM doesn't use this, even it used 2 encoder
		 * as for that dsi_sw43404_amoled_cmd, for ex */
		/* qcom,mdss-dsc-encoders = <2>; */
		qcom,mdss-dsc-version = <0x11>;
		qcom,mdss-dsc-slice-height = <20>;
		qcom,mdss-dsc-slice-width = <540>;
		qcom,mdss-dsc-slice-per-pkt = <2>;
		qcom,mdss-dsc-bit-per-component = <10>;
		qcom,mdss-dsc-bit-per-pixel = <8>;
		qcom,mdss-dsc-block-prediction-enable;
		qcom,mdss-dsc-novateck-ic;

		qcom,mdss-dsi-pcd-check-enable-command = [
			39 00 00 40 00 00 06 F0 55 AA 52 08 01
			39 00 00 40 00 00 02 6F 01
			39 00 00 00 00 00 06 D0 80 00 30 00 01
			];
		qcom,mdss-dsi-pcd-check-enable-command-state = "dsi_hs_mode";
		qcom,mdss-dsi-pcd-check-disable-command = [
			39 00 00 40 00 00 06 F0 55 AA 52 08 01
			39 00 00 40 00 00 02 6F 01
			39 00 00 00 00 00 06 D0 00 00 30 00 01
			];
		qcom,mdss-dsi-pcd-check-disable-command-state = "dsi_hs_mode";
	};

	timing@4{
		qcom,mdss-dsi-cmd-mode;
		qcom,mdss-dsi-panel-framerate = <30>;
		qcom,mdss-dsi-panel-width = <1080>;
		qcom,mdss-dsi-panel-height = <2520>;
		qcom,mdss-dsi-h-front-porch = <96>;
		qcom,mdss-dsi-h-back-porch = <64>;
		qcom,mdss-dsi-h-pulse-width = <32>;
		qcom,mdss-dsi-h-sync-skew = <0>;
		qcom,mdss-dsi-h-sync-pulse = <0>;
		qcom,mdss-dsi-v-back-porch = <28>;
		qcom,mdss-dsi-v-front-porch = <44>;
		qcom,mdss-dsi-v-pulse-width = <4>;
		qcom,mdss-dsi-h-left-border = <0>;
		qcom,mdss-dsi-h-right-border = <0>;
		qcom,mdss-dsi-v-top-border = <0>;
		qcom,mdss-dsi-v-bottom-border = <0>;
		qcom,mdss-dsi-timing-switch-command = [
			39 00 00 40 00 00 02 6F 04
			39 00 00 40 00 00 02 35 03
			39 00 00 40 00 00 02 53 28
			39 00 00 40 00 00 02 5A 00
			39 00 00 40 00 00 02 2F 30
			39 00 00 40 00 00 03 6D 03 00
			39 00 00 40 00 00 02 6F 06
			39 00 00 40 00 00 02 6D 00
			39 00 00 40 00 00 02 6F 02
			39 00 00 40 00 00 02 8C 10
			39 00 00 40 00 00 02 8C 00
			39 00 00 40 00 00 06 F0 55 AA 52 08 00
			39 00 00 40 00 00 02 6F 05
			39 00 00 00 00 00 03 B2 04 04
		];
		qcom,mdss-dsi-on-command = [
		39 00 00 40 00 00 06 F0 55 AA 52 08 01
		39 00 00 40 00 00 02 6F 2F
		39 00 00 40 00 00 02 C3 00
		39 00 00 40 00 00 02 6F 00
		39 00 00 40 00 00 06 C3 99 29 02 60 E3
		39 00 00 40 00 00 02 6F 06
		39 00 00 40 00 00 02 C3 29
		39 00 00 40 00 00 02 6F 08
		39 00 00 40 00 00 03 C3 60 E3
		39 00 00 40 00 00 02 6F 0B
		39 00 00 40 00 00 25 C3 3F 41 2A 3F 52 EB 3F 1D DF 3F 3B B0 3F 41 95 3F 0D 75 3F 4B 9A 3F 4C 43 3F 41 95 3F 0D 75 01 10 00 00 10 00
		39 00 00 40 00 00 02 6F 30
		39 00 00 40 00 00 06 C3 00 AA 02 AA 02
		39 00 00 40 00 00 02 6F 00
		39 00 00 40 00 00 02 C3 DD
		39 00 00 40 00 00 02 6F 04
		39 00 00 40 00 00 02 C3 07
		39 00 00 40 00 00 02 6F 09
		39 00 00 40 00 00 02 C3 07
		39 00 00 40 00 00 06 F0 55 AA 52 08 01
		39 00 00 40 00 00 04 C4 00 92 00
		39 00 00 40 00 00 02 6F 06
		39 00 00 40 00 00 02 8D 05
		39 00 00 40 00 00 06 F0 55 AA 52 08 00
		39 00 00 40 00 00 03 B2 09 60
		39 00 00 40 00 00 02 6F 05
		39 00 00 40 00 00 03 B2 05 05

		39 00 00 40 00 00 06 F0 55 AA 52 08 09
		39 00 00 40 00 00 03 D0 FF 00
		39 00 00 40 00 00 02 6F 02
		39 00 00 40 00 00 03 D0 06 64
		39 00 00 40 00 00 02 6F 04
		39 00 00 40 00 00 03 D0 09 04
		39 00 00 40 00 00 02 6F 06
		39 00 00 40 00 00 03 D0 0D BF
		39 00 00 40 00 00 02 6F 08
		39 00 00 40 00 00 03 D0 0D C0
		39 00 00 40 00 00 02 6F 0A
		39 00 00 40 00 00 03 D0 1D 24
		39 00 00 40 00 00 02 6F 0C
		39 00 00 40 00 00 03 D0 2C 50
		39 00 00 40 00 00 02 6F 0E
		39 00 00 40 00 00 07 D0 10 00 00 00 00 00
		39 00 00 40 00 00 02 6F 14
		39 00 00 40 00 00 07 D0 10 00 00 00 00 00
		39 00 00 40 00 00 02 6F 1A
		39 00 00 40 00 00 07 D0 00 00 00 00 00 00
		39 00 00 40 00 00 02 6F 20
		39 00 00 40 00 00 07 D0 00 00 00 00 00 00
		39 00 00 40 00 00 02 6F 26
		39 00 00 40 00 00 07 D0 1F 00 00 00 00 00
		39 00 00 40 00 00 02 6F 2C
		39 00 00 40 00 00 07 D0 1F 00 00 00 00 00
		39 00 00 40 00 00 02 6F 32
		39 00 00 40 00 00 07 D0 00 00 00 00 00 00
		39 00 00 40 00 00 02 6F 38
		39 00 00 40 00 00 07 D0 00 00 00 00 00 00
		39 00 00 40 00 00 02 62 80

		39 00 00 40 00 00 06 F0 55 AA 52 08 00
		39 00 00 40 00 00 02 6F 78
		39 00 00 40 00 00 18 B0 10 00 2A 00 C2 01 DA 03 7C 05 B1 08 80 0B EE 0F FF 05 55 05 56 05 55
		39 00 00 40 00 00 02 6F 6F
		39 00 00 40 00 00 07 B0 02 1C 04 38 02 1C
		39 00 00 40 00 00 06 F0 55 AA 52 08 08
		39 00 00 40 00 00 17 C1 8D FF DD FF FF DD FF FF DD FF FF DD FF FF DD FF FF AB FC 45 0D FF
		39 00 00 40 00 00 02 6F 23
		39 00 00 40 00 00 15 C1 0D FF DD FF FF DD FF FF DD FF FF DD FF FF DD FF FF AB FC 45
		39 00 00 40 00 00 02 6F 37
		39 00 00 40 00 00 15 C1 0D FF DD FF FF DD FF FF DD FF FF DD FF FF DD FF FF FF FF FF
		39 00 00 40 00 00 02 6F 4B
		39 00 00 40 00 00 15 C1 0D FF DD FF FF DD FF FF DD FF FF DD FF FF DD FF FF AB FC 45
		39 00 00 40 00 00 02 6F 5F
		39 00 00 40 00 00 15 C1 0D FF DD FF FF DD FF FF DD FF FF DD FF FF DD FF FF FF FF FF
		39 00 00 40 00 00 02 6F 73
		39 00 00 40 00 00 15 C1 0D FF DD FF FF DD FF FF DD FF FF DD FF FF DD FF FF AB FC 45
		39 00 00 40 00 00 11 BA 00 01 03 A4 03 A4 05 B8 05 B8 07 D8 07 D8 0A 84
		39 00 00 40 00 00 02 6F 10
		39 00 00 40 00 00 11 BA 0A 84 0D BF 0D BF 0D C0 0D C0 1D 24 1D 24 2C 50
		39 00 00 40 00 00 02 6F 20
		39 00 00 40 00 00 0D BA 2C 50 36 E8 36 E8 3C 34 3C 34 3F FC
		39 00 00 40 00 00 02 6F 20
		39 00 00 40 00 00 04 C1 04 52 CD
		39 00 00 40 00 00 02 6F 1D
		39 00 00 40 00 00 04 C1 00 80 FF
		39 00 00 40 00 00 02 6F 07
		39 00 00 40 00 00 02 51 00
		39 00 00 40 00 00 06 F0 55 AA 52 08 00
		39 00 00 40 00 00 02 C7 22
		39 00 00 40 00 00 02 6F 31
		39 00 00 40 00 00 03 C0 00 12
		39 00 00 40 00 00 02 6F 35
		39 00 00 40 00 00 03 C0 33 34
		39 00 00 40 00 00 06 F0 55 AA 52 08 04
		39 00 00 40 00 00 02 C0 20
		39 00 00 40 00 00 02 B1 01
		39 00 00 40 00 00 02 6F 0A
		39 00 00 40 00 00 02 B1 20
		39 00 00 40 00 00 02 6F 07
		39 00 00 40 00 00 04 B1 00 02 1C
		39 00 00 40 00 00 02 6F 0B
		39 00 00 40 00 00 02 B1 02
		39 00 00 40 00 00 02 C4 10
		39 00 00 40 00 00 05 FF AA 55 A5 80
		39 00 00 40 00 00 02 6F 0A
		39 00 00 40 00 00 06 F6 70 70 70 70 70
		39 00 00 40 00 00 02 6F 07
		39 00 00 40 00 00 02 F8 4D
		39 00 00 40 00 00 02 6F 23
		39 00 00 40 00 00 02 F8 4D
		39 00 00 40 00 00 05 FF AA 55 A5 81
		39 00 00 40 00 00 02 6F 0C
		39 00 00 40 00 00 02 FD 08
		39 00 00 40 00 00 02 6F 10
		39 00 00 40 00 00 02 FB 40
		39 00 00 40 00 00 02 6F 13
		39 00 00 40 00 00 02 F9 00
		39 00 00 40 00 00 02 17 30
		39 00 00 40 00 00 05 2A 00 00 04 37
		39 00 00 40 00 00 05 2B 00 00 09 D7
		39 00 00 40 00 00 02 90 03
		39 00 00 40 00 00 02 6F 01
		39 00 00 40 00 00 02 90 43
		39 00 00 40 00 00 13 91 AB A8 00 14 C2 00 02 0E 01 E8 00 07 05 0E 05 16 10 F0
		39 00 00 40 00 00 02 6F 06
		39 00 00 40 00 00 02 6D 04

		39 00 00 40 00 00 02 6F 04
		39 00 00 40 00 00 02 35 03
		39 00 00 40 00 00 02 53 28
		39 00 00 40 00 00 02 5A 00
		39 00 00 40 00 00 02 2F 30
		39 00 00 40 00 00 03 6D 03 00
		39 00 00 40 00 00 02 6F 06
		39 00 00 40 00 00 02 6D 00
		39 00 00 40 00 00 02 6F 02
		39 00 00 40 00 00 02 8C 10
		39 00 00 40 00 00 02 8C 00
		39 00 00 40 00 00 06 F0 55 AA 52 08 00
		39 00 00 40 00 00 02 6F 05
		39 00 00 40 00 00 03 B2 04 04

		39 00 00 40 00 00 03 5F 00 00
		//39 00 00 40 00 00 02 35 00
		39 00 00 40 00 00 03 51 00 00
		39 00 00 40 00 00 02 6F 04
		39 00 00 40 00 00 03 51 3F FC
		//39 00 00 40 00 00 02 53 20
		39 00 00 40 00 00 06 F0 55 AA 52 08 01
		39 00 00 40 00 00 02 6F 02
		39 00 00 40 00 00 03 C7 00 00
		39 00 00 00 00 00 02 26 00
                05 00 00 00 78 00 01 11
                05 00 00 00 00 00 01 29];	/* display on */
		qcom,mdss-dsi-off-command = [
			05 00 00 00 00 00 01 28		/* display_off */
			05 00 00 00 64 00 01 10];	/* enter sleep mode */

		qcom,mdss-dsi-on-command-state = "dsi_lp_mode";
		qcom,mdss-dsi-off-command-state = "dsi_lp_mode";
		qcom,mdss-dsi-timing-switch-command-state =
			"dsi_hs_mode";
		qcom,compression-mode = "dsc";
		/* Why QCOM doesn't use this, even it used 2 encoder
		 * as for that dsi_sw43404_amoled_cmd, for ex */
		/* qcom,mdss-dsc-encoders = <2>; */
		qcom,mdss-dsc-version = <0x11>;
		qcom,mdss-dsc-slice-height = <20>;
		qcom,mdss-dsc-slice-width = <540>;
		qcom,mdss-dsc-slice-per-pkt = <2>;
		qcom,mdss-dsc-bit-per-component = <10>;
		qcom,mdss-dsc-bit-per-pixel = <8>;
		qcom,mdss-dsc-block-prediction-enable;
		qcom,mdss-dsc-novateck-ic;

		qcom,mdss-dsi-pcd-check-enable-command = [
			39 00 00 40 00 00 06 F0 55 AA 52 08 01
			39 00 00 40 00 00 02 6F 01
			39 00 00 00 00 00 06 D0 80 00 30 00 01
			];
		qcom,mdss-dsi-pcd-check-enable-command-state = "dsi_hs_mode";
		qcom,mdss-dsi-pcd-check-disable-command = [
			39 00 00 40 00 00 06 F0 55 AA 52 08 01
			39 00 00 40 00 00 02 6F 01
			39 00 00 00 00 00 06 D0 00 00 30 00 01
			];
		qcom,mdss-dsi-pcd-check-disable-command-state = "dsi_hs_mode";
	};

	timing@5{
		qcom,mdss-dsi-cmd-mode;
		qcom,mdss-dsi-panel-framerate = <24>;
		qcom,mdss-dsi-panel-width = <1080>;
		qcom,mdss-dsi-panel-height = <2520>;
		qcom,mdss-dsi-h-front-porch = <96>;
		qcom,mdss-dsi-h-back-porch = <64>;
		qcom,mdss-dsi-h-pulse-width = <32>;
		qcom,mdss-dsi-h-sync-skew = <0>;
		qcom,mdss-dsi-h-sync-pulse = <0>;
		qcom,mdss-dsi-v-back-porch = <28>;
		qcom,mdss-dsi-v-front-porch = <44>;
		qcom,mdss-dsi-v-pulse-width = <4>;
		qcom,mdss-dsi-h-left-border = <0>;
		qcom,mdss-dsi-h-right-border = <0>;
		qcom,mdss-dsi-v-top-border = <0>;
		qcom,mdss-dsi-v-bottom-border = <0>;
		qcom,mdss-dsi-timing-switch-command = [
			39 00 00 40 00 00 02 6F 04
			39 00 00 40 00 00 02 35 04
			39 00 00 40 00 00 02 53 28
			39 00 00 40 00 00 02 5A 00
			39 00 00 40 00 00 02 2F 30
			39 00 00 40 00 00 03 6D 04 00
			39 00 00 40 00 00 02 6F 06
			39 00 00 40 00 00 02 6D 00
			39 00 00 40 00 00 02 6F 02
			39 00 00 40 00 00 02 8C 10
			39 00 00 40 00 00 02 8C 00
			39 00 00 40 00 00 06 F0 55 AA 52 08 00
			39 00 00 40 00 00 02 6F 05
			39 00 00 00 00 00 03 B2 05 05
		];
		qcom,mdss-dsi-on-command = [
		39 00 00 40 00 00 06 F0 55 AA 52 08 01
		39 00 00 40 00 00 02 6F 2F
		39 00 00 40 00 00 02 C3 00
		39 00 00 40 00 00 02 6F 00
		39 00 00 40 00 00 06 C3 99 29 02 60 E3
		39 00 00 40 00 00 02 6F 06
		39 00 00 40 00 00 02 C3 29
		39 00 00 40 00 00 02 6F 08
		39 00 00 40 00 00 03 C3 60 E3
		39 00 00 40 00 00 02 6F 0B
		39 00 00 40 00 00 25 C3 3F 41 2A 3F 52 EB 3F 1D DF 3F 3B B0 3F 41 95 3F 0D 75 3F 4B 9A 3F 4C 43 3F 41 95 3F 0D 75 01 10 00 00 10 00
		39 00 00 40 00 00 02 6F 30
		39 00 00 40 00 00 06 C3 00 AA 02 AA 02
		39 00 00 40 00 00 02 6F 00
		39 00 00 40 00 00 02 C3 DD
		39 00 00 40 00 00 02 6F 04
		39 00 00 40 00 00 02 C3 07
		39 00 00 40 00 00 02 6F 09
		39 00 00 40 00 00 02 C3 07
		39 00 00 40 00 00 06 F0 55 AA 52 08 01
		39 00 00 40 00 00 04 C4 00 92 00
		39 00 00 40 00 00 02 6F 06
		39 00 00 40 00 00 02 8D 05
		39 00 00 40 00 00 06 F0 55 AA 52 08 00
		39 00 00 40 00 00 03 B2 09 60
		39 00 00 40 00 00 02 6F 05
		39 00 00 40 00 00 03 B2 05 05

		39 00 00 40 00 00 06 F0 55 AA 52 08 09
		39 00 00 40 00 00 03 D0 FF 00
		39 00 00 40 00 00 02 6F 02
		39 00 00 40 00 00 03 D0 06 64
		39 00 00 40 00 00 02 6F 04
		39 00 00 40 00 00 03 D0 09 04
		39 00 00 40 00 00 02 6F 06
		39 00 00 40 00 00 03 D0 0D BF
		39 00 00 40 00 00 02 6F 08
		39 00 00 40 00 00 03 D0 0D C0
		39 00 00 40 00 00 02 6F 0A
		39 00 00 40 00 00 03 D0 1D 24
		39 00 00 40 00 00 02 6F 0C
		39 00 00 40 00 00 03 D0 2C 50
		39 00 00 40 00 00 02 6F 0E
		39 00 00 40 00 00 07 D0 10 00 00 00 00 00
		39 00 00 40 00 00 02 6F 14
		39 00 00 40 00 00 07 D0 10 00 00 00 00 00
		39 00 00 40 00 00 02 6F 1A
		39 00 00 40 00 00 07 D0 00 00 00 00 00 00
		39 00 00 40 00 00 02 6F 20
		39 00 00 40 00 00 07 D0 00 00 00 00 00 00
		39 00 00 40 00 00 02 6F 26
		39 00 00 40 00 00 07 D0 1F 00 00 00 00 00
		39 00 00 40 00 00 02 6F 2C
		39 00 00 40 00 00 07 D0 1F 00 00 00 00 00
		39 00 00 40 00 00 02 6F 32
		39 00 00 40 00 00 07 D0 00 00 00 00 00 00
		39 00 00 40 00 00 02 6F 38
		39 00 00 40 00 00 07 D0 00 00 00 00 00 00
		39 00 00 40 00 00 02 62 80

		39 00 00 40 00 00 06 F0 55 AA 52 08 00
		39 00 00 40 00 00 02 6F 78
		39 00 00 40 00 00 18 B0 10 00 2A 00 C2 01 DA 03 7C 05 B1 08 80 0B EE 0F FF 05 55 05 56 05 55
		39 00 00 40 00 00 02 6F 6F
		39 00 00 40 00 00 07 B0 02 1C 04 38 02 1C
		39 00 00 40 00 00 06 F0 55 AA 52 08 08
		39 00 00 40 00 00 17 C1 8D FF DD FF FF DD FF FF DD FF FF DD FF FF DD FF FF AB FC 45 0D FF
		39 00 00 40 00 00 02 6F 23
		39 00 00 40 00 00 15 C1 0D FF DD FF FF DD FF FF DD FF FF DD FF FF DD FF FF AB FC 45
		39 00 00 40 00 00 02 6F 37
		39 00 00 40 00 00 15 C1 0D FF DD FF FF DD FF FF DD FF FF DD FF FF DD FF FF FF FF FF
		39 00 00 40 00 00 02 6F 4B
		39 00 00 40 00 00 15 C1 0D FF DD FF FF DD FF FF DD FF FF DD FF FF DD FF FF AB FC 45
		39 00 00 40 00 00 02 6F 5F
		39 00 00 40 00 00 15 C1 0D FF DD FF FF DD FF FF DD FF FF DD FF FF DD FF FF FF FF FF
		39 00 00 40 00 00 02 6F 73
		39 00 00 40 00 00 15 C1 0D FF DD FF FF DD FF FF DD FF FF DD FF FF DD FF FF AB FC 45
		39 00 00 40 00 00 11 BA 00 01 03 A4 03 A4 05 B8 05 B8 07 D8 07 D8 0A 84
		39 00 00 40 00 00 02 6F 10
		39 00 00 40 00 00 11 BA 0A 84 0D BF 0D BF 0D C0 0D C0 1D 24 1D 24 2C 50
		39 00 00 40 00 00 02 6F 20
		39 00 00 40 00 00 0D BA 2C 50 36 E8 36 E8 3C 34 3C 34 3F FC
		39 00 00 40 00 00 02 6F 20
		39 00 00 40 00 00 04 C1 04 52 CD
		39 00 00 40 00 00 02 6F 1D
		39 00 00 40 00 00 04 C1 00 80 FF
		39 00 00 40 00 00 02 6F 07
		39 00 00 40 00 00 02 51 00
		39 00 00 40 00 00 06 F0 55 AA 52 08 00
		39 00 00 40 00 00 02 C7 22
		39 00 00 40 00 00 02 6F 31
		39 00 00 40 00 00 03 C0 00 12
		39 00 00 40 00 00 02 6F 35
		39 00 00 40 00 00 03 C0 33 34
		39 00 00 40 00 00 06 F0 55 AA 52 08 04
		39 00 00 40 00 00 02 C0 20
		39 00 00 40 00 00 02 B1 01
		39 00 00 40 00 00 02 6F 0A
		39 00 00 40 00 00 02 B1 20
		39 00 00 40 00 00 02 6F 07
		39 00 00 40 00 00 04 B1 00 02 1C
		39 00 00 40 00 00 02 6F 0B
		39 00 00 40 00 00 02 B1 02
		39 00 00 40 00 00 02 C4 10
		39 00 00 40 00 00 05 FF AA 55 A5 80
		39 00 00 40 00 00 02 6F 0A
		39 00 00 40 00 00 06 F6 70 70 70 70 70
		39 00 00 40 00 00 02 6F 07
		39 00 00 40 00 00 02 F8 4D
		39 00 00 40 00 00 02 6F 23
		39 00 00 40 00 00 02 F8 4D
		39 00 00 40 00 00 05 FF AA 55 A5 81
		39 00 00 40 00 00 02 6F 0C
		39 00 00 40 00 00 02 FD 08
		39 00 00 40 00 00 02 6F 10
		39 00 00 40 00 00 02 FB 40
		39 00 00 40 00 00 02 6F 13
		39 00 00 40 00 00 02 F9 00
		39 00 00 40 00 00 02 17 30
		39 00 00 40 00 00 05 2A 00 00 04 37
		39 00 00 40 00 00 05 2B 00 00 09 D7
		39 00 00 40 00 00 02 90 03
		39 00 00 40 00 00 02 6F 01
		39 00 00 40 00 00 02 90 43
		39 00 00 40 00 00 13 91 AB A8 00 14 C2 00 02 0E 01 E8 00 07 05 0E 05 16 10 F0
		39 00 00 40 00 00 02 6F 06
		39 00 00 40 00 00 02 6D 04

		39 00 00 40 00 00 02 6F 04
		39 00 00 40 00 00 02 35 04
		39 00 00 40 00 00 02 53 28
		39 00 00 40 00 00 02 5A 00
		39 00 00 40 00 00 02 2F 30
		39 00 00 40 00 00 03 6D 04 00
		39 00 00 40 00 00 02 6F 06
		39 00 00 40 00 00 02 6D 00
		39 00 00 40 00 00 02 6F 02
		39 00 00 40 00 00 02 8C 10
		39 00 00 40 00 00 02 8C 00
		39 00 00 40 00 00 06 F0 55 AA 52 08 00
		39 00 00 40 00 00 02 6F 05
		39 00 00 40 00 00 03 B2 05 05

		39 00 00 40 00 00 03 5F 00 00
		//39 00 00 40 00 00 02 35 00
		39 00 00 40 00 00 03 51 00 00
		39 00 00 40 00 00 02 6F 04
		39 00 00 40 00 00 03 51 3F FC
		//39 00 00 40 00 00 02 53 20
		39 00 00 40 00 00 06 F0 55 AA 52 08 01
		39 00 00 40 00 00 02 6F 02
		39 00 00 40 00 00 03 C7 00 00
		39 00 00 00 00 00 02 26 00
                05 00 00 00 78 00 01 11
                05 00 00 00 00 00 01 29];	/* display on */
		qcom,mdss-dsi-off-command = [
			05 00 00 00 00 00 01 28		/* display_off */
			05 00 00 00 64 00 01 10];	/* enter sleep mode */

		qcom,mdss-dsi-on-command-state = "dsi_lp_mode";
		qcom,mdss-dsi-off-command-state = "dsi_lp_mode";
		qcom,mdss-dsi-timing-switch-command-state =
			"dsi_hs_mode";
		qcom,compression-mode = "dsc";
		/* Why QCOM doesn't use this, even it used 2 encoder
		 * as for that dsi_sw43404_amoled_cmd, for ex */
		/* qcom,mdss-dsc-encoders = <2>; */
		qcom,mdss-dsc-version = <0x11>;
		qcom,mdss-dsc-slice-height = <20>;
		qcom,mdss-dsc-slice-width = <540>;
		qcom,mdss-dsc-slice-per-pkt = <2>;
		qcom,mdss-dsc-bit-per-component = <10>;
		qcom,mdss-dsc-bit-per-pixel = <8>;
		qcom,mdss-dsc-block-prediction-enable;
		qcom,mdss-dsc-novateck-ic;

		qcom,mdss-dsi-pcd-check-enable-command = [
			39 00 00 40 00 00 06 F0 55 AA 52 08 01
			39 00 00 40 00 00 02 6F 01
			39 00 00 00 00 00 06 D0 80 00 30 00 01
			];
		qcom,mdss-dsi-pcd-check-enable-command-state = "dsi_hs_mode";
		qcom,mdss-dsi-pcd-check-disable-command = [
			39 00 00 40 00 00 06 F0 55 AA 52 08 01
			39 00 00 40 00 00 02 6F 01
			39 00 00 00 00 00 06 D0 00 00 30 00 01
			];
		qcom,mdss-dsi-pcd-check-disable-command-state = "dsi_hs_mode";
	};

	timing@6{
		qcom,mdss-dsi-cmd-mode;
		qcom,mdss-dsi-panel-framerate = <120>;  /* Actually 10 hz*/
		qcom,mdss-dsi-panel-width = <1080>;
		qcom,mdss-dsi-panel-height = <2520>;
		qcom,mdss-dsi-h-front-porch = <96>;
		qcom,mdss-dsi-h-back-porch = <64>;
		qcom,mdss-dsi-h-pulse-width = <30>;
		qcom,mdss-dsi-h-sync-skew = <0>;
		qcom,mdss-dsi-h-sync-pulse = <0>;
		qcom,mdss-dsi-v-back-porch = <28>;
		qcom,mdss-dsi-v-front-porch = <44>;
		qcom,mdss-dsi-v-pulse-width = <4>;
		qcom,mdss-dsi-h-left-border = <0>;
		qcom,mdss-dsi-h-right-border = <0>;
		qcom,mdss-dsi-v-top-border = <0>;
		qcom,mdss-dsi-v-bottom-border = <0>;
		qcom,mdss-dsi-timing-switch-command = [
			39 00 00 40 00 00 02 6F 04
			39 00 00 40 00 00 02 35 00
			39 00 00 40 00 00 02 53 20
			39 00 00 40 00 00 02 5A 00
			39 00 00 40 00 00 02 6F 06
			39 00 00 40 00 00 02 6D 00
			39 00 00 40 00 00 02 2F 30
			39 00 00 40 00 00 03 6D 08 00
			39 00 00 40 00 00 02 6F 02
			39 00 00 40 00 00 02 8C 10
			39 00 00 00 00 00 02 8C 00
		];
		qcom,mdss-dsi-on-command = [
		39 00 00 40 00 00 06 F0 55 AA 52 08 01
		39 00 00 40 00 00 02 6F 2F
		39 00 00 40 00 00 02 C3 00
		39 00 00 40 00 00 02 6F 00
		39 00 00 40 00 00 06 C3 99 29 02 60 E3
		39 00 00 40 00 00 02 6F 06
		39 00 00 40 00 00 02 C3 29
		39 00 00 40 00 00 02 6F 08
		39 00 00 40 00 00 03 C3 60 E3
		39 00 00 40 00 00 02 6F 0B
		39 00 00 40 00 00 25 C3 3F 41 2A 3F 52 EB 3F 1D DF 3F 3B B0 3F 41 95 3F 0D 75 3F 4B 9A 3F 4C 43 3F 41 95 3F 0D 75 01 10 00 00 10 00
		39 00 00 40 00 00 02 6F 30
		39 00 00 40 00 00 06 C3 00 AA 02 AA 02
		39 00 00 40 00 00 02 6F 00
		39 00 00 40 00 00 02 C3 DD
		39 00 00 40 00 00 02 6F 04
		39 00 00 40 00 00 02 C3 07
		39 00 00 40 00 00 02 6F 09
		39 00 00 40 00 00 02 C3 07
		39 00 00 40 00 00 06 F0 55 AA 52 08 01
		39 00 00 40 00 00 04 C4 00 92 00
		39 00 00 40 00 00 02 6F 06
		39 00 00 40 00 00 02 8D 05
		39 00 00 40 00 00 06 F0 55 AA 52 08 00
		39 00 00 40 00 00 03 B2 09 60
		39 00 00 40 00 00 02 6F 05
		39 00 00 40 00 00 03 B2 05 05

		39 00 00 40 00 00 06 F0 55 AA 52 08 09
		39 00 00 40 00 00 03 D0 FF 00
		39 00 00 40 00 00 02 6F 02
		39 00 00 40 00 00 03 D0 06 64
		39 00 00 40 00 00 02 6F 04
		39 00 00 40 00 00 03 D0 09 04
		39 00 00 40 00 00 02 6F 06
		39 00 00 40 00 00 03 D0 0D BF
		39 00 00 40 00 00 02 6F 08
		39 00 00 40 00 00 03 D0 0D C0
		39 00 00 40 00 00 02 6F 0A
		39 00 00 40 00 00 03 D0 1D 24
		39 00 00 40 00 00 02 6F 0C
		39 00 00 40 00 00 03 D0 2C 50
		39 00 00 40 00 00 02 6F 0E
		39 00 00 40 00 00 07 D0 10 00 00 00 00 00
		39 00 00 40 00 00 02 6F 14
		39 00 00 40 00 00 07 D0 10 00 00 00 00 00
		39 00 00 40 00 00 02 6F 1A
		39 00 00 40 00 00 07 D0 00 00 00 00 00 00
		39 00 00 40 00 00 02 6F 20
		39 00 00 40 00 00 07 D0 00 00 00 00 00 00
		39 00 00 40 00 00 02 6F 26
		39 00 00 40 00 00 07 D0 1F 00 00 00 00 00
		39 00 00 40 00 00 02 6F 2C
		39 00 00 40 00 00 07 D0 1F 00 00 00 00 00
		39 00 00 40 00 00 02 6F 32
		39 00 00 40 00 00 07 D0 00 00 00 00 00 00
		39 00 00 40 00 00 02 6F 38
		39 00 00 40 00 00 07 D0 00 00 00 00 00 00
		39 00 00 40 00 00 02 62 80

		39 00 00 40 00 00 06 F0 55 AA 52 08 00
		39 00 00 40 00 00 02 6F 78
		39 00 00 40 00 00 18 B0 10 00 2A 00 C2 01 DA 03 7C 05 B1 08 80 0B EE 0F FF 05 55 05 56 05 55
		39 00 00 40 00 00 02 6F 6F
		39 00 00 40 00 00 07 B0 02 1C 04 38 02 1C
		39 00 00 40 00 00 06 F0 55 AA 52 08 08
		39 00 00 40 00 00 17 C1 8D FF DD FF FF DD FF FF DD FF FF DD FF FF DD FF FF AB FC 45 0D FF
		39 00 00 40 00 00 02 6F 23
		39 00 00 40 00 00 15 C1 0D FF DD FF FF DD FF FF DD FF FF DD FF FF DD FF FF AB FC 45
		39 00 00 40 00 00 02 6F 37
		39 00 00 40 00 00 15 C1 0D FF DD FF FF DD FF FF DD FF FF DD FF FF DD FF FF FF FF FF
		39 00 00 40 00 00 02 6F 4B
		39 00 00 40 00 00 15 C1 0D FF DD FF FF DD FF FF DD FF FF DD FF FF DD FF FF AB FC 45
		39 00 00 40 00 00 02 6F 5F
		39 00 00 40 00 00 15 C1 0D FF DD FF FF DD FF FF DD FF FF DD FF FF DD FF FF FF FF FF
		39 00 00 40 00 00 02 6F 73
		39 00 00 40 00 00 15 C1 0D FF DD FF FF DD FF FF DD FF FF DD FF FF DD FF FF AB FC 45
		39 00 00 40 00 00 11 BA 00 01 03 A4 03 A4 05 B8 05 B8 07 D8 07 D8 0A 84
		39 00 00 40 00 00 02 6F 10
		39 00 00 40 00 00 11 BA 0A 84 0D BF 0D BF 0D C0 0D C0 1D 24 1D 24 2C 50
		39 00 00 40 00 00 02 6F 20
		39 00 00 40 00 00 0D BA 2C 50 36 E8 36 E8 3C 34 3C 34 3F FC
		39 00 00 40 00 00 02 6F 20
		39 00 00 40 00 00 04 C1 04 52 CD
		39 00 00 40 00 00 02 6F 1D
		39 00 00 40 00 00 04 C1 00 80 FF
		39 00 00 40 00 00 02 6F 07
		39 00 00 40 00 00 02 51 00
		39 00 00 40 00 00 06 F0 55 AA 52 08 00
		39 00 00 40 00 00 02 C7 22
		39 00 00 40 00 00 02 6F 31
		39 00 00 40 00 00 03 C0 00 12
		39 00 00 40 00 00 02 6F 35
		39 00 00 40 00 00 03 C0 33 34
		39 00 00 40 00 00 06 F0 55 AA 52 08 04
		39 00 00 40 00 00 02 C0 20
		39 00 00 40 00 00 02 B1 01
		39 00 00 40 00 00 02 6F 0A
		39 00 00 40 00 00 02 B1 20
		39 00 00 40 00 00 02 6F 07
		39 00 00 40 00 00 04 B1 00 02 1C
		39 00 00 40 00 00 02 6F 0B
		39 00 00 40 00 00 02 B1 02
		39 00 00 40 00 00 02 C4 10
		39 00 00 40 00 00 05 FF AA 55 A5 80
		39 00 00 40 00 00 02 6F 0A
		39 00 00 40 00 00 06 F6 70 70 70 70 70
		39 00 00 40 00 00 02 6F 07
		39 00 00 40 00 00 02 F8 4D
		39 00 00 40 00 00 02 6F 23
		39 00 00 40 00 00 02 F8 4D
		39 00 00 40 00 00 05 FF AA 55 A5 81
		39 00 00 40 00 00 02 6F 0C
		39 00 00 40 00 00 02 FD 08
		39 00 00 40 00 00 02 6F 10
		39 00 00 40 00 00 02 FB 40
		39 00 00 40 00 00 02 6F 13
		39 00 00 40 00 00 02 F9 00
		39 00 00 40 00 00 02 17 30
		39 00 00 40 00 00 05 2A 00 00 04 37
		39 00 00 40 00 00 05 2B 00 00 09 D7
		39 00 00 40 00 00 02 90 03
		39 00 00 40 00 00 02 6F 01
		39 00 00 40 00 00 02 90 43
		39 00 00 40 00 00 13 91 AB A8 00 14 C2 00 02 0E 01 E8 00 07 05 0E 05 16 10 F0
		39 00 00 40 00 00 02 6F 06
		39 00 00 40 00 00 02 6D 04

		39 00 00 40 00 00 02 6F 04
		39 00 00 40 00 00 02 35 00
		39 00 00 40 00 00 02 53 20
		39 00 00 40 00 00 02 5A 00
		39 00 00 40 00 00 02 6F 06
		39 00 00 40 00 00 02 6D 00
		39 00 00 40 00 00 02 2F 30
		39 00 00 40 00 00 03 6D 08 00
		39 00 00 40 00 00 02 6F 02
		39 00 00 40 00 00 02 8C 10
		39 00 00 40 00 00 02 8C 00

		39 00 00 40 00 00 03 5F 00 00
		//39 00 00 40 00 00 02 35 00
		39 00 00 40 00 00 03 51 00 00
		39 00 00 40 00 00 02 6F 04
		39 00 00 40 00 00 03 51 3F FC
		//39 00 00 40 00 00 02 53 20
		39 00 00 40 00 00 06 F0 55 AA 52 08 01
		39 00 00 40 00 00 02 6F 02
		39 00 00 40 00 00 03 C7 00 00
		39 00 00 00 00 00 02 26 00
                05 00 00 00 78 00 01 11
                05 00 00 00 00 00 01 29];	/* display on */
		qcom,mdss-dsi-off-command = [
			05 00 00 00 00 00 01 28		/* display_off */
			05 00 00 00 64 00 01 10];	/* enter sleep mode */

		qcom,mdss-dsi-on-command-state = "dsi_lp_mode";
		qcom,mdss-dsi-off-command-state = "dsi_lp_mode";
		qcom,mdss-dsi-timing-switch-command-state =
			"dsi_hs_mode";
		qcom,compression-mode = "dsc";
		/* Why QCOM doesn't use this, even it used 2 encoder
		 * as for that dsi_sw43404_amoled_cmd, for ex */
		/* qcom,mdss-dsc-encoders = <2>; */
		qcom,mdss-dsc-version = <0x11>;
		qcom,mdss-dsc-slice-height = <20>;
		qcom,mdss-dsc-slice-width = <540>;
		qcom,mdss-dsc-slice-per-pkt = <2>;
		qcom,mdss-dsc-bit-per-component = <10>;
		qcom,mdss-dsc-bit-per-pixel = <8>;
		qcom,mdss-dsc-block-prediction-enable;
		qcom,mdss-dsc-novateck-ic;

		qcom,mdss-dsi-pcd-check-enable-command = [
			39 00 00 40 00 00 06 F0 55 AA 52 08 01
			39 00 00 40 00 00 02 6F 01
			39 00 00 00 00 00 06 D0 80 00 30 00 01
			];
		qcom,mdss-dsi-pcd-check-enable-command-state = "dsi_hs_mode";
		qcom,mdss-dsi-pcd-check-disable-command = [
			39 00 00 40 00 00 06 F0 55 AA 52 08 01
			39 00 00 40 00 00 02 6F 01
			39 00 00 00 00 00 06 D0 00 00 30 00 01
			];
		qcom,mdss-dsi-pcd-check-disable-command-state = "dsi_hs_mode";
	};

	timing@7{
		qcom,mdss-dsi-cmd-mode;
		qcom,mdss-dsi-panel-framerate = <120>; /* Actually 1 hz*/
		qcom,mdss-dsi-panel-width = <1080>;
		qcom,mdss-dsi-panel-height = <2520>;
		qcom,mdss-dsi-h-front-porch = <96>;
		qcom,mdss-dsi-h-back-porch = <64>;
		qcom,mdss-dsi-h-pulse-width = <28>;
		qcom,mdss-dsi-h-sync-skew = <0>;
		qcom,mdss-dsi-h-sync-pulse = <0>;
		qcom,mdss-dsi-v-back-porch = <28>;
		qcom,mdss-dsi-v-front-porch = <44>;
		qcom,mdss-dsi-v-pulse-width = <4>;
		qcom,mdss-dsi-h-left-border = <0>;
		qcom,mdss-dsi-h-right-border = <0>;
		qcom,mdss-dsi-v-top-border = <0>;
		qcom,mdss-dsi-v-bottom-border = <0>;
		qcom,mdss-dsi-timing-switch-command = [
			39 00 00 40 00 00 02 6F 04
			39 00 00 40 00 00 02 35 00
			39 00 00 40 00 00 02 53 20
			39 00 00 40 00 00 02 5A 00
			39 00 00 40 00 00 02 6F 06
			39 00 00 40 00 00 02 6D 00
			39 00 00 40 00 00 02 2F 30
			39 00 00 40 00 00 03 6D 09 00
			39 00 00 40 00 00 02 6F 02
			39 00 00 40 00 00 02 8C 10
			39 00 00 00 00 00 02 8C 00
		];
		qcom,mdss-dsi-on-command = [
		39 00 00 40 00 00 06 F0 55 AA 52 08 01
		39 00 00 40 00 00 02 6F 2F
		39 00 00 40 00 00 02 C3 00
		39 00 00 40 00 00 02 6F 00
		39 00 00 40 00 00 06 C3 99 29 02 60 E3
		39 00 00 40 00 00 02 6F 06
		39 00 00 40 00 00 02 C3 29
		39 00 00 40 00 00 02 6F 08
		39 00 00 40 00 00 03 C3 60 E3
		39 00 00 40 00 00 02 6F 0B
		39 00 00 40 00 00 25 C3 3F 41 2A 3F 52 EB 3F 1D DF 3F 3B B0 3F 41 95 3F 0D 75 3F 4B 9A 3F 4C 43 3F 41 95 3F 0D 75 01 10 00 00 10 00
		39 00 00 40 00 00 02 6F 30
		39 00 00 40 00 00 06 C3 00 AA 02 AA 02
		39 00 00 40 00 00 02 6F 00
		39 00 00 40 00 00 02 C3 DD
		39 00 00 40 00 00 02 6F 04
		39 00 00 40 00 00 02 C3 07
		39 00 00 40 00 00 02 6F 09
		39 00 00 40 00 00 02 C3 07
		39 00 00 40 00 00 06 F0 55 AA 52 08 01
		39 00 00 40 00 00 04 C4 00 92 00
		39 00 00 40 00 00 02 6F 06
		39 00 00 40 00 00 02 8D 05
		39 00 00 40 00 00 06 F0 55 AA 52 08 00
		39 00 00 40 00 00 03 B2 09 60
		39 00 00 40 00 00 02 6F 05
		39 00 00 40 00 00 03 B2 05 05

		39 00 00 40 00 00 06 F0 55 AA 52 08 09
		39 00 00 40 00 00 03 D0 FF 00
		39 00 00 40 00 00 02 6F 02
		39 00 00 40 00 00 03 D0 06 64
		39 00 00 40 00 00 02 6F 04
		39 00 00 40 00 00 03 D0 09 04
		39 00 00 40 00 00 02 6F 06
		39 00 00 40 00 00 03 D0 0D BF
		39 00 00 40 00 00 02 6F 08
		39 00 00 40 00 00 03 D0 0D C0
		39 00 00 40 00 00 02 6F 0A
		39 00 00 40 00 00 03 D0 1D 24
		39 00 00 40 00 00 02 6F 0C
		39 00 00 40 00 00 03 D0 2C 50
		39 00 00 40 00 00 02 6F 0E
		39 00 00 40 00 00 07 D0 10 00 00 00 00 00
		39 00 00 40 00 00 02 6F 14
		39 00 00 40 00 00 07 D0 10 00 00 00 00 00
		39 00 00 40 00 00 02 6F 1A
		39 00 00 40 00 00 07 D0 00 00 00 00 00 00
		39 00 00 40 00 00 02 6F 20
		39 00 00 40 00 00 07 D0 00 00 00 00 00 00
		39 00 00 40 00 00 02 6F 26
		39 00 00 40 00 00 07 D0 1F 00 00 00 00 00
		39 00 00 40 00 00 02 6F 2C
		39 00 00 40 00 00 07 D0 1F 00 00 00 00 00
		39 00 00 40 00 00 02 6F 32
		39 00 00 40 00 00 07 D0 00 00 00 00 00 00
		39 00 00 40 00 00 02 6F 38
		39 00 00 40 00 00 07 D0 00 00 00 00 00 00
		39 00 00 40 00 00 02 62 80

		39 00 00 40 00 00 06 F0 55 AA 52 08 00
		39 00 00 40 00 00 02 6F 78
		39 00 00 40 00 00 18 B0 10 00 2A 00 C2 01 DA 03 7C 05 B1 08 80 0B EE 0F FF 05 55 05 56 05 55
		39 00 00 40 00 00 02 6F 6F
		39 00 00 40 00 00 07 B0 02 1C 04 38 02 1C
		39 00 00 40 00 00 06 F0 55 AA 52 08 08
		39 00 00 40 00 00 17 C1 8D FF DD FF FF DD FF FF DD FF FF DD FF FF DD FF FF AB FC 45 0D FF
		39 00 00 40 00 00 02 6F 23
		39 00 00 40 00 00 15 C1 0D FF DD FF FF DD FF FF DD FF FF DD FF FF DD FF FF AB FC 45
		39 00 00 40 00 00 02 6F 37
		39 00 00 40 00 00 15 C1 0D FF DD FF FF DD FF FF DD FF FF DD FF FF DD FF FF FF FF FF
		39 00 00 40 00 00 02 6F 4B
		39 00 00 40 00 00 15 C1 0D FF DD FF FF DD FF FF DD FF FF DD FF FF DD FF FF AB FC 45
		39 00 00 40 00 00 02 6F 5F
		39 00 00 40 00 00 15 C1 0D FF DD FF FF DD FF FF DD FF FF DD FF FF DD FF FF FF FF FF
		39 00 00 40 00 00 02 6F 73
		39 00 00 40 00 00 15 C1 0D FF DD FF FF DD FF FF DD FF FF DD FF FF DD FF FF AB FC 45
		39 00 00 40 00 00 11 BA 00 01 03 A4 03 A4 05 B8 05 B8 07 D8 07 D8 0A 84
		39 00 00 40 00 00 02 6F 10
		39 00 00 40 00 00 11 BA 0A 84 0D BF 0D BF 0D C0 0D C0 1D 24 1D 24 2C 50
		39 00 00 40 00 00 02 6F 20
		39 00 00 40 00 00 0D BA 2C 50 36 E8 36 E8 3C 34 3C 34 3F FC
		39 00 00 40 00 00 02 6F 20
		39 00 00 40 00 00 04 C1 04 52 CD
		39 00 00 40 00 00 02 6F 1D
		39 00 00 40 00 00 04 C1 00 80 FF
		39 00 00 40 00 00 02 6F 07
		39 00 00 40 00 00 02 51 00
		39 00 00 40 00 00 06 F0 55 AA 52 08 00
		39 00 00 40 00 00 02 C7 22
		39 00 00 40 00 00 02 6F 31
		39 00 00 40 00 00 03 C0 00 12
		39 00 00 40 00 00 02 6F 35
		39 00 00 40 00 00 03 C0 33 34
		39 00 00 40 00 00 06 F0 55 AA 52 08 04
		39 00 00 40 00 00 02 C0 20
		39 00 00 40 00 00 02 B1 01
		39 00 00 40 00 00 02 6F 0A
		39 00 00 40 00 00 02 B1 20
		39 00 00 40 00 00 02 6F 07
		39 00 00 40 00 00 04 B1 00 02 1C
		39 00 00 40 00 00 02 6F 0B
		39 00 00 40 00 00 02 B1 02
		39 00 00 40 00 00 02 C4 10
		39 00 00 40 00 00 05 FF AA 55 A5 80
		39 00 00 40 00 00 02 6F 0A
		39 00 00 40 00 00 06 F6 70 70 70 70 70
		39 00 00 40 00 00 02 6F 07
		39 00 00 40 00 00 02 F8 4D
		39 00 00 40 00 00 02 6F 23
		39 00 00 40 00 00 02 F8 4D
		39 00 00 40 00 00 05 FF AA 55 A5 81
		39 00 00 40 00 00 02 6F 0C
		39 00 00 40 00 00 02 FD 08
		39 00 00 40 00 00 02 6F 10
		39 00 00 40 00 00 02 FB 40
		39 00 00 40 00 00 02 6F 13
		39 00 00 40 00 00 02 F9 00
		39 00 00 40 00 00 02 17 30
		39 00 00 40 00 00 05 2A 00 00 04 37
		39 00 00 40 00 00 05 2B 00 00 09 D7
		39 00 00 40 00 00 02 90 03
		39 00 00 40 00 00 02 6F 01
		39 00 00 40 00 00 02 90 43
		39 00 00 40 00 00 13 91 AB A8 00 14 C2 00 02 0E 01 E8 00 07 05 0E 05 16 10 F0
		39 00 00 40 00 00 02 6F 06
		39 00 00 40 00 00 02 6D 04

		39 00 00 40 00 00 02 6F 04
		39 00 00 40 00 00 02 35 00
		39 00 00 40 00 00 02 53 20
		39 00 00 40 00 00 02 5A 00
		39 00 00 40 00 00 02 6F 06
		39 00 00 40 00 00 02 6D 00
		39 00 00 40 00 00 02 2F 30
		39 00 00 40 00 00 03 6D 09 00
		39 00 00 40 00 00 02 6F 02
		39 00 00 40 00 00 02 8C 10
		39 00 00 40 00 00 02 8C 00

		39 00 00 40 00 00 03 5F 00 00
		//39 00 00 40 00 00 02 35 00
		39 00 00 40 00 00 03 51 00 00
		39 00 00 40 00 00 02 6F 04
		39 00 00 40 00 00 03 51 3F FC
		//39 00 00 40 00 00 02 53 20
		39 00 00 40 00 00 06 F0 55 AA 52 08 01
		39 00 00 40 00 00 02 6F 02
		39 00 00 40 00 00 03 C7 00 00
		39 00 00 00 00 00 02 26 00
                05 00 00 00 78 00 01 11
                05 00 00 00 00 00 01 29];	/* display on */
		qcom,mdss-dsi-off-command = [
			05 00 00 00 00 00 01 28		/* display_off */
			05 00 00 00 64 00 01 10];	/* enter sleep mode */

		qcom,mdss-dsi-on-command-state = "dsi_lp_mode";
		qcom,mdss-dsi-off-command-state = "dsi_lp_mode";
		qcom,mdss-dsi-timing-switch-command-state =
			"dsi_hs_mode";
		qcom,compression-mode = "dsc";
		/* Why QCOM doesn't use this, even it used 2 encoder
		 * as for that dsi_sw43404_amoled_cmd, for ex */
		/* qcom,mdss-dsc-encoders = <2>; */
		qcom,mdss-dsc-version = <0x11>;
		qcom,mdss-dsc-slice-height = <20>;
		qcom,mdss-dsc-slice-width = <540>;
		qcom,mdss-dsc-slice-per-pkt = <2>;
		qcom,mdss-dsc-bit-per-component = <10>;
		qcom,mdss-dsc-bit-per-pixel = <8>;
		qcom,mdss-dsc-block-prediction-enable;
		qcom,mdss-dsc-novateck-ic;

		qcom,mdss-dsi-pcd-check-enable-command = [
			39 00 00 40 00 00 06 F0 55 AA 52 08 01
			39 00 00 40 00 00 02 6F 01
			39 00 00 00 00 00 06 D0 80 00 30 00 01
			];
		qcom,mdss-dsi-pcd-check-enable-command-state = "dsi_hs_mode";
		qcom,mdss-dsi-pcd-check-disable-command = [
			39 00 00 40 00 00 06 F0 55 AA 52 08 01
			39 00 00 40 00 00 02 6F 01
			39 00 00 00 00 00 06 D0 00 00 30 00 01
			];
		qcom,mdss-dsi-pcd-check-disable-command-state = "dsi_hs_mode";
	};
};

};

};
